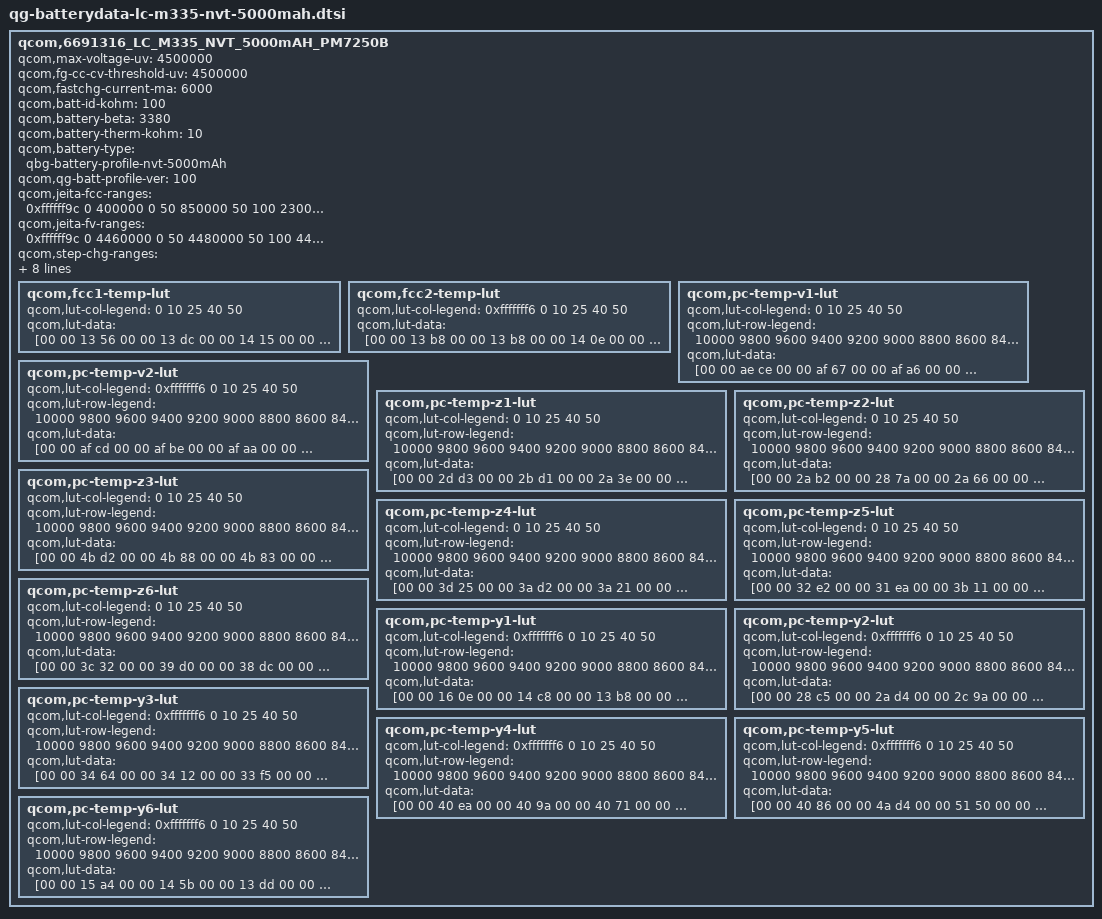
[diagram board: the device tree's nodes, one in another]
// SPDX-License-Identifier: GPL-2.0-only
/* QG battery profile qcom,6691316_LC_M335_NVT_5000mAH_PM7250B (sapphire, reconstructed from stock dtbo) */

qcom,6691316_LC_M335_NVT_5000mAH_PM7250B {
	qcom,max-voltage-uv = <4500000>;
	qcom,fg-cc-cv-threshold-uv = <4500000>;
	qcom,fastchg-current-ma = <6000>;
	qcom,batt-id-kohm = <100>;
	qcom,battery-beta = <3380>;
	qcom,battery-therm-kohm = <10>;
	qcom,battery-type = "qbg-battery-profile-nvt-5000mAh";
	qcom,qg-batt-profile-ver = <100>;
	qcom,jeita-fcc-ranges = <0xffffff9c 0 400000 0 50 850000 50 100
	                         2300000 100 150 3700000 150 350 6000000 350
	                         480 6000000 480 560 2300000>;
	qcom,jeita-fv-ranges = <0xffffff9c 0 4460000 0 50 4480000 50 100
	                        4480000 100 150 4480000 150 350 4450000 350
	                        480 4450000 480 560 4100000>;
	qcom,step-chg-ranges = <3600000 4250000 6000000 4250001 4480000 5400000 4480001 4500000
	                        3920000>;
	qcom,vbat-avg-based-step-chg;
	qcom,taper-fcc;
	qcom,jeita-soft-thresholds = <9556 3725>;
	qcom,jeita-hard-thresholds = <17365 2971>;
	qcom,jeita-soft-hys-thresholds = <8799 4060>;
	qcom,jeita-soft-fcc-ua = <5400000 2500000>;
	qcom,jeita-soft-fv-uv = <4480000 4100000>;

	qcom,fcc1-temp-lut {
		qcom,lut-col-legend = <0 10 25 40 50>;
		qcom,lut-data = [00 00 13 56 00 00 13 dc 00 00 14 15 00 00 14 32 00 00 14 3c];
	};

	qcom,fcc2-temp-lut {
		qcom,lut-col-legend = <0xfffffff6 0 10 25 40 50>;
		qcom,lut-data = [00 00 13 b8 00 00 13 b8 00 00 14 0e 00 00 14 2a 00 00 14 1b 00 00 14 12];
	};

	qcom,pc-temp-v1-lut {
		qcom,lut-col-legend = <0 10 25 40 50>;
		qcom,lut-row-legend = <10000 9800 9600 9400 9200 9000 8800 8600
		                       8400 8200 8000 7800 7600 7400 7200 7000
		                       6800 6600 6400 6200 6000 5800 5600 5400
		                       5200 5000 4800 4600 4400 4200 4000 3800
		                       3600 3400 3200 3000 2800 2600 2400 2200
		                       2000 1800 1600 1400 1200 1000 900 800
		                       700 600 500 400 300 200 100 0>;
		qcom,lut-data = [00 00 ae ce 00 00 af 67 00 00 af a6 00 00 af c5 00 00 af c9 00 00 ad b2 00 00 ad e1 00 00 ae 0c 00 00 ae 1d 00 00 ae 22 00 00 ac b0 00 00 ac e7 00 00 ac eb 00 00 ac e9 00 00 ac f2 00 00 ab d3 00 00 ac 14 00 00 ac 0c 00 00 ab fd 00 00 ac 03 00 00 ab 06 00 00 ab 38 00 00 ab 33 00 00 ab 23 00 00 ab 26 00 00 aa 2b 00 00 aa 61 00 00 aa 57 00 00 aa 47 00 00 aa 48 00 00 a9 44 00 00 a9 80 00 00 a9 78 00 00 a9 6e 00 00 a9 6e 00 00 a8 56 00 00 a8 90 00 00 a8 8c 00 00 a8 86 00 00 a8 89 00 00 a7 60 00 00 a7 97 00 00 a7 94 00 00 a7 90 00 00 a7 99 00 00 a6 65 00 00 a6 9d 00 00 a6 9a 00 00 a6 96 00 00 a6 a2 00 00 a5 6d 00 00 a5 9f 00 00 a5 9d 00 00 a5 9b 00 00 a5 a8 00 00 a4 78 00 00 a4 a4 00 00 a4 a0 00 00 a4 a0 00 00 a4 ad 00 00 a3 86 00 00 a3 ac 00 00 a3 a5 00 00 a3 a6 00 00 a3 b5 00 00 a2 9d 00 00 a2 b9 00 00 a2 ad 00 00 a2 ae 00 00 a2 bf 00 00 a1 bb 00 00 a1 cf 00 00 a1 bf 00 00 a1 bd 00 00 a1 cf 00 00 a0 de 00 00 a0 eb 00 00 a0 d7 00 00 a0 d4 00 00 a0 e4 00 00 a0 07 00 00 a0 0f 00 00 9f f7 00 00 9f f1 00 00 9f ff 00 00 9f 37 00 00 9f 3b 00 00 9f 1f 00 00 9f 17 00 00 9f 23 00 00 9e 70 00 00 9e 6f 00 00 9e 4f 00 00 9e 44 00 00 9e 4f 00 00 9d b0 00 00 9d b1 00 00 9d 8b 00 00 9d 7b 00 00 9d 84 00 00 9c f5 00 00 9c fa 00 00 9c d5 00 00 9c c3 00 00 9c ca 00 00 9c 45 00 00 9c 34 00 00 9c 0f 00 00 9b ff 00 00 9c 07 00 00 9b 8c 00 00 9b 5c 00 00 9b 1e 00 00 9b 17 00 00 9b 24 00 00 9a 9c 00 00 9a 7f 00 00 9a 2b 00 00 9a 25 00 00 9a 35 00 00 99 83 00 00 99 97 00 00 99 61 00 00 99 57 00 00 99 66 00 00 98 b3 00 00 98 b6 00 00 98 b0 00 00 98 9e 00 00 98 ab 00 00 98 29 00 00 98 1f 00 00 98 1d 00 00 98 03 00 00 98 0c 00 00 97 bb 00 00 97 ba 00 00 97 a3 00 00 97 83 00 00 97 87 00 00 97 5d 00 00 97 5b 00 00 97 36 00 00 97 13 00 00 97 13 00 00 97 0c 00 00 96 f5 00 00 96 ce 00 00 96 a9 00 00 96 a5 00 00 96 c1 00 00 96 94 00 00 96 6e 00 00 96 49 00 00 96 40 00 00 96 76 00 00 96 3f 00 00 96 1a 00 00 95 ef 00 00 95 e4 00 00 96 30 00 00 95 f5 00 00 95 d0 00 00 95 9d 00 00 95 91 00 00 95 ee 00 00 95 b2 00 00 95 8c 00 00 95 52 00 00 95 43 00 00 95 b1 00 00 95 78 00 00 95 4e 00 00 95 10 00 00 94 fc 00 00 95 7a 00 00 95 43 00 00 95 15 00 00 94 d3 00 00 94 b9 00 00 95 4e 00 00 95 12 00 00 94 dd 00 00 94 91 00 00 94 6c 00 00 95 23 00 00 94 e5 00 00 94 aa 00 00 94 4c 00 00 94 16 00 00 94 ec 00 00 94 aa 00 00 94 6b 00 00 93 fe 00 00 93 ba 00 00 94 a8 00 00 94 53 00 00 94 13 00 00 93 a2 00 00 93 5b 00 00 94 54 00 00 93 e8 00 00 93 a8 00 00 93 39 00 00 92 f2 00 00 93 da 00 00 93 70 00 00 93 2f 00 00 92 bf 00 00 92 76 00 00 93 49 00 00 92 e1 00 00 92 a1 00 00 92 30 00 00 91 e5 00 00 92 a6 00 00 92 33 00 00 91 f6 00 00 91 8c 00 00 91 46 00 00 92 09 00 00 91 8a 00 00 91 55 00 00 90 f7 00 00 90 b7 00 00 91 72 00 00 91 12 00 00 90 ef 00 00 90 9f 00 00 90 63 00 00 91 35 00 00 90 ed 00 00 90 d3 00 00 90 88 00 00 90 4d 00 00 91 09 00 00 90 d5 00 00 90 be 00 00 90 79 00 00 90 3d 00 00 90 e0 00 00 90 bc 00 00 90 a5 00 00 90 61 00 00 90 23 00 00 90 b7 00 00 90 7a 00 00 90 56 00 00 8f de 00 00 8f 8a 00 00 90 7d 00 00 8f 62 00 00 8f 32 00 00 8e 81 00 00 8e 25 00 00 8f 9e 00 00 8d 7f 00 00 8d 64 00 00 8c 99 00 00 8c 3d 00 00 8d bb 00 00 8a fd 00 00 8b 08 00 00 8a 22 00 00 89 c4 00 00 8a af 00 00 87 6a 00 00 87 cd 00 00 86 b7 00 00 86 60 00 00 80 47 00 00 81 76 00 00 82 c3 00 00 81 4e 00 00 80 f7 00 00 75 30 00 00 75 30 00 00 75 30 00 00 75 30 00 00 75 30];
	};

	qcom,pc-temp-v2-lut {
		qcom,lut-col-legend = <0xfffffff6 0 10 25 40 50>;
		qcom,lut-row-legend = <10000 9800 9600 9400 9200 9000 8800 8600
		                       8400 8200 8000 7800 7600 7400 7200 7000
		                       6800 6600 6400 6200 6000 5800 5600 5400
		                       5200 5000 4800 4600 4400 4200 4000 3800
		                       3600 3400 3200 3000 2800 2600 2400 2200
		                       2000 1800 1600 1400 1200 1000 900 800
		                       700 600 500 400 300 200 100 0>;
		qcom,lut-data = [00 00 af cd 00 00 af be 00 00 af aa 00 00 af 7d 00 00 af 64 00 00 af 50 00 00 ad d1 00 00 ad ee 00 00 ad ee 00 00 ad f3 00 00 ad d3 00 00 ad c1 00 00 ac 2e 00 00 ac 6f 00 00 ac 7f 00 00 ac a5 00 00 ac 7e 00 00 ac 6e 00 00 aa ff 00 00 ab 59 00 00 ab 72 00 00 ab a2 00 00 ab 72 00 00 ab 61 00 00 aa 20 00 00 aa 8e 00 00 aa a9 00 00 aa d6 00 00 aa 9f 00 00 aa 8d 00 00 a9 49 00 00 a9 c4 00 00 a9 dd 00 00 aa 07 00 00 a9 ca 00 00 a9 b7 00 00 a8 5f 00 00 a8 e0 00 00 a8 f9 00 00 a9 25 00 00 a8 e5 00 00 a8 d2 00 00 a7 73 00 00 a7 f4 00 00 a8 0d 00 00 a8 3c 00 00 a7 fa 00 00 a7 e9 00 00 a6 81 00 00 a7 02 00 00 a7 19 00 00 a7 49 00 00 a7 07 00 00 a6 f7 00 00 a5 87 00 00 a6 08 00 00 a6 1b 00 00 a6 4c 00 00 a6 0b 00 00 a5 fc 00 00 a4 8e 00 00 a5 0f 00 00 a5 1d 00 00 a5 4f 00 00 a5 10 00 00 a5 02 00 00 a3 95 00 00 a4 16 00 00 a4 20 00 00 a4 52 00 00 a4 14 00 00 a4 08 00 00 a2 9f 00 00 a3 1e 00 00 a3 26 00 00 a3 56 00 00 a3 1b 00 00 a3 10 00 00 a1 ba 00 00 a2 2c 00 00 a2 31 00 00 a2 5f 00 00 a2 27 00 00 a2 1d 00 00 a0 e2 00 00 a1 3e 00 00 a1 42 00 00 a1 6c 00 00 a1 37 00 00 a1 2e 00 00 a0 05 00 00 a0 5a 00 00 a0 59 00 00 a0 81 00 00 a0 4f 00 00 a0 46 00 00 9f 20 00 00 9f 86 00 00 9f 74 00 00 9f 9d 00 00 9f 6e 00 00 9f 64 00 00 9e 31 00 00 9e b7 00 00 9e 98 00 00 9e c0 00 00 9e 94 00 00 9e 8b 00 00 9d 2e 00 00 9d e5 00 00 9d cc 00 00 9d ef 00 00 9d c4 00 00 9d bd 00 00 9c 18 00 00 9d 10 00 00 9d 03 00 00 9d 20 00 00 9c f8 00 00 9c f5 00 00 9b 12 00 00 9c 26 00 00 9c 1d 00 00 9c 4b 00 00 9c 30 00 00 9c 2f 00 00 9a 21 00 00 9b 0b 00 00 9b 15 00 00 9b 72 00 00 9b 6b 00 00 9b 6d 00 00 99 3f 00 00 99 f2 00 00 9a 19 00 00 9a 8d 00 00 9a 97 00 00 9a 9c 00 00 98 65 00 00 99 14 00 00 99 2e 00 00 99 86 00 00 99 91 00 00 99 9a 00 00 97 96 00 00 98 52 00 00 98 59 00 00 98 93 00 00 98 97 00 00 98 9f 00 00 96 e6 00 00 97 a8 00 00 97 ac 00 00 97 e6 00 00 97 ea 00 00 97 f2 00 00 96 50 00 00 97 12 00 00 97 1c 00 00 97 5a 00 00 97 62 00 00 97 6b 00 00 95 d1 00 00 96 89 00 00 96 99 00 00 96 da 00 00 96 e6 00 00 96 ef 00 00 95 6d 00 00 96 0a 00 00 96 21 00 00 96 63 00 00 96 74 00 00 96 7c 00 00 95 19 00 00 95 96 00 00 95 b3 00 00 95 f7 00 00 96 0b 00 00 96 12 00 00 94 ce 00 00 95 2b 00 00 95 4e 00 00 95 96 00 00 95 ac 00 00 95 b1 00 00 94 8a 00 00 94 c5 00 00 94 f0 00 00 95 3d 00 00 95 54 00 00 95 56 00 00 94 4b 00 00 94 6d 00 00 94 9a 00 00 94 e9 00 00 95 03 00 00 95 03 00 00 94 0d 00 00 94 2c 00 00 94 4a 00 00 94 99 00 00 94 b9 00 00 94 ba 00 00 93 d1 00 00 93 f8 00 00 94 01 00 00 94 49 00 00 94 6a 00 00 94 69 00 00 93 90 00 00 93 c6 00 00 93 c1 00 00 93 fb 00 00 94 0a 00 00 93 fb 00 00 93 4a 00 00 93 97 00 00 93 85 00 00 93 ab 00 00 93 a2 00 00 93 7b 00 00 92 ff 00 00 93 65 00 00 93 45 00 00 93 4f 00 00 93 37 00 00 93 05 00 00 92 ac 00 00 93 26 00 00 92 ff 00 00 92 ea 00 00 92 c8 00 00 92 95 00 00 92 51 00 00 92 dc 00 00 92 af 00 00 92 87 00 00 92 5e 00 00 92 2a 00 00 91 ec 00 00 92 7c 00 00 92 49 00 00 92 2b 00 00 92 04 00 00 91 cd 00 00 91 7a 00 00 91 f8 00 00 91 d1 00 00 91 c0 00 00 91 9e 00 00 91 68 00 00 91 00 00 00 91 66 00 00 91 42 00 00 91 3a 00 00 91 1c 00 00 90 e5 00 00 90 81 00 00 90 c7 00 00 90 9d 00 00 90 9d 00 00 90 84 00 00 90 4a 00 00 90 15 00 00 90 33 00 00 90 12 00 00 90 28 00 00 90 15 00 00 8f e1 00 00 8f ac 00 00 8f c1 00 00 8f c5 00 00 90 06 00 00 8f f9 00 00 8f c5 00 00 8f 79 00 00 8f 8e 00 00 8f 9e 00 00 8f ef 00 00 8f e5 00 00 8f b1 00 00 8f 42 00 00 8f 5f 00 00 8f 6b 00 00 8f cd 00 00 8f cd 00 00 8f 97 00 00 8f 34 00 00 8f 2b 00 00 8f 26 00 00 8f 7b 00 00 8f 97 00 00 8f 5a 00 00 8e d3 00 00 8e ed 00 00 8e 68 00 00 8e 77 00 00 8e b3 00 00 8e 6d 00 00 90 35 00 00 8e 84 00 00 8c e0 00 00 8c a0 00 00 8d 00 00 00 8c b1 00 00 8e ed 00 00 8d aa 00 00 8a 8f 00 00 8a 3c 00 00 8a cc 00 00 8a 7e 00 00 91 23 00 00 8d b4 00 00 87 81 00 00 87 0b 00 00 87 d5 00 00 87 8c 00 00 7a 6a 00 00 8b ff 00 00 84 a3 00 00 82 47 00 00 83 a5 00 00 83 77 00 00 76 38 00 00 77 c9 00 00 7e f6 00 00 7b e9 00 00 7d 77 00 00 7d 66 00 00 72 44 00 00 72 8c 00 00 6d d8 00 00 71 d6 00 00 6d 9a 00 00 6d a1];
	};

	qcom,pc-temp-z1-lut {
		qcom,lut-col-legend = <0 10 25 40 50>;
		qcom,lut-row-legend = <10000 9800 9600 9400 9200 9000 8800 8600
		                       8400 8200 8000 7800 7600 7400 7200 7000
		                       6800 6600 6400 6200 6000 5800 5600 5400
		                       5200 5000 4800 4600 4400 4200 4000 3800
		                       3600 3400 3200 3000 2800 2600 2400 2200
		                       2000 1800 1600 1400 1200 1000 900 800
		                       700 600 500 400 300 200 100 0>;
		qcom,lut-data = [00 00 2d d3 00 00 2b d1 00 00 2a 3e 00 00 29 82 00 00 29 68 00 00 2d e1 00 00 2c 0a 00 00 2a 58 00 00 29 a5 00 00 29 88 00 00 2d ea 00 00 2b fa 00 00 2a 57 00 00 29 9e 00 00 29 85 00 00 2d ed 00 00 2b e4 00 00 2a 4d 00 00 29 99 00 00 29 84 00 00 2d ef 00 00 2b e0 00 00 2a 44 00 00 29 97 00 00 29 83 00 00 2d ef 00 00 2b e0 00 00 2a 3d 00 00 29 97 00 00 29 84 00 00 2d e6 00 00 2b df 00 00 2a 38 00 00 29 98 00 00 29 86 00 00 2d d8 00 00 2b d3 00 00 2a 35 00 00 29 99 00 00 29 89 00 00 2d c0 00 00 2b c3 00 00 2a 34 00 00 29 9b 00 00 29 8c 00 00 2d 9e 00 00 2b bd 00 00 2a 33 00 00 29 9d 00 00 29 90 00 00 2d 8e 00 00 2b b9 00 00 2a 36 00 00 29 a0 00 00 29 94 00 00 2d 87 00 00 2b b7 00 00 2a 39 00 00 29 a4 00 00 29 99 00 00 2d 83 00 00 2b b9 00 00 2a 3e 00 00 29 a8 00 00 29 9d 00 00 2d 84 00 00 2b bb 00 00 2a 43 00 00 29 ad 00 00 29 a2 00 00 2d 85 00 00 2b c0 00 00 2a 49 00 00 29 b2 00 00 29 a6 00 00 2d 85 00 00 2b c7 00 00 2a 50 00 00 29 b7 00 00 29 ac 00 00 2d 84 00 00 2b cd 00 00 2a 58 00 00 29 bc 00 00 29 b2 00 00 2d 85 00 00 2b d2 00 00 2a 5d 00 00 29 c1 00 00 29 b7 00 00 2d 8a 00 00 2b d8 00 00 2a 62 00 00 29 c7 00 00 29 bc 00 00 2d 94 00 00 2b dd 00 00 2a 69 00 00 29 cc 00 00 29 c1 00 00 2d 9d 00 00 2b e5 00 00 2a 70 00 00 29 d2 00 00 29 c6 00 00 2d a4 00 00 2b ea 00 00 2a 77 00 00 29 d7 00 00 29 ca 00 00 2d ad 00 00 2b ef 00 00 2a 7b 00 00 29 db 00 00 29 cf 00 00 2d bb 00 00 2b f3 00 00 2a 7f 00 00 29 df 00 00 29 d3 00 00 2d cd 00 00 2b f5 00 00 2a 86 00 00 29 e3 00 00 29 d7 00 00 2d d3 00 00 2b f7 00 00 2a 8d 00 00 29 e8 00 00 29 da 00 00 2d cb 00 00 2b f9 00 00 2a 94 00 00 29 ec 00 00 29 de 00 00 2d c2 00 00 2b fd 00 00 2a 9a 00 00 29 f0 00 00 29 e2 00 00 2d c3 00 00 2c 01 00 00 2a 9f 00 00 29 f4 00 00 29 e5 00 00 2d c9 00 00 2c 0a 00 00 2a a4 00 00 29 f8 00 00 29 e8 00 00 2d ce 00 00 2c 16 00 00 2a a9 00 00 29 fc 00 00 29 ec 00 00 2d d6 00 00 2c 17 00 00 2a af 00 00 2a 00 00 00 29 ef 00 00 2d de 00 00 2c 13 00 00 2a b5 00 00 2a 03 00 00 29 f2 00 00 2d e0 00 00 2c 11 00 00 2a bb 00 00 2a 07 00 00 29 f4 00 00 2d de 00 00 2c 16 00 00 2a c0 00 00 2a 0b 00 00 29 f7 00 00 2d de 00 00 2c 1e 00 00 2a c5 00 00 2a 0f 00 00 29 fa 00 00 2d e7 00 00 2c 24 00 00 2a cb 00 00 2a 13 00 00 29 fd 00 00 2d f4 00 00 2c 29 00 00 2a d2 00 00 2a 17 00 00 2a 00 00 00 2d fe 00 00 2c 2f 00 00 2a d9 00 00 2a 1a 00 00 2a 02 00 00 2e 08 00 00 2c 38 00 00 2a df 00 00 2a 1c 00 00 2a 03 00 00 2e 0f 00 00 2c 41 00 00 2a e3 00 00 2a 1e 00 00 2a 05 00 00 2e 14 00 00 2c 47 00 00 2a e7 00 00 2a 21 00 00 2a 06 00 00 2e 17 00 00 2c 4d 00 00 2a e9 00 00 2a 23 00 00 2a 08 00 00 2e 20 00 00 2c 5e 00 00 2a f1 00 00 2a 26 00 00 2a 0a 00 00 2e 40 00 00 2c 66 00 00 2a f7 00 00 2a 29 00 00 2a 0b 00 00 2e 33 00 00 2c 63 00 00 2a f8 00 00 2a 2a 00 00 2a 0d 00 00 2e 3d 00 00 2c 6a 00 00 2b 00 00 00 2a 2a 00 00 2a 0d 00 00 2e 4c 00 00 2c 6d 00 00 2a fb 00 00 2a 2c 00 00 2a 0d 00 00 2e 3c 00 00 2c 64 00 00 2b 00 00 00 2a 2e 00 00 2a 0f 00 00 2e 4b 00 00 2c 64 00 00 2b 04 00 00 2a 30 00 00 2a 10 00 00 2e 42 00 00 2c 6e 00 00 2b 09 00 00 2a 33 00 00 2a 12 00 00 2e 53 00 00 2c 7e 00 00 2b 0e 00 00 2a 38 00 00 2a 15 00 00 2e 5f 00 00 2c 83 00 00 2b 18 00 00 2a 3c 00 00 2a 19 00 00 2e 58 00 00 2c aa 00 00 2b 22 00 00 2a 42 00 00 2a 1f 00 00 2e 58 00 00 2c aa 00 00 2b 22 00 00 2a 42 00 00 2a 1f 00 00 2e 58 00 00 2c aa 00 00 2b 22 00 00 2a 42 00 00 2a 1f];
	};

	qcom,pc-temp-z2-lut {
		qcom,lut-col-legend = <0 10 25 40 50>;
		qcom,lut-row-legend = <10000 9800 9600 9400 9200 9000 8800 8600
		                       8400 8200 8000 7800 7600 7400 7200 7000
		                       6800 6600 6400 6200 6000 5800 5600 5400
		                       5200 5000 4800 4600 4400 4200 4000 3800
		                       3600 3400 3200 3000 2800 2600 2400 2200
		                       2000 1800 1600 1400 1200 1000 900 800
		                       700 600 500 400 300 200 100 0>;
		qcom,lut-data = [00 00 2a b2 00 00 28 7a 00 00 2a 66 00 00 2c 9f 00 00 2c de 00 00 29 d1 00 00 29 8f 00 00 2a fc 00 00 2b 6c 00 00 2c 7d 00 00 29 61 00 00 29 da 00 00 2b 56 00 00 2c 99 00 00 2c 84 00 00 29 5b 00 00 2a 09 00 00 2b 22 00 00 2c 7f 00 00 2c ed 00 00 29 4d 00 00 2a 05 00 00 2a f0 00 00 2c 60 00 00 2d 58 00 00 29 3c 00 00 29 da 00 00 2a c6 00 00 2c 3a 00 00 2d 46 00 00 29 1d 00 00 29 b3 00 00 2a aa 00 00 2c 0b 00 00 2d 01 00 00 28 ff 00 00 29 98 00 00 2a a9 00 00 2c 06 00 00 2c eb 00 00 28 eb 00 00 29 85 00 00 2a ad 00 00 2c 1d 00 00 2c e0 00 00 28 da 00 00 29 87 00 00 2a ac 00 00 2c 2a 00 00 2c d7 00 00 28 d6 00 00 29 94 00 00 2a 9f 00 00 2c 22 00 00 2c d8 00 00 28 dd 00 00 29 9f 00 00 2a 96 00 00 2c 13 00 00 2c dd 00 00 28 e6 00 00 29 a6 00 00 2a 99 00 00 2c 07 00 00 2c df 00 00 28 ee 00 00 29 ad 00 00 2a 9e 00 00 2b fc 00 00 2c e4 00 00 28 fc 00 00 29 b8 00 00 2a a2 00 00 2b f7 00 00 2c ef 00 00 29 08 00 00 29 c6 00 00 2a a4 00 00 2b f7 00 00 2d 1a 00 00 29 12 00 00 29 d1 00 00 2a a6 00 00 2b f8 00 00 2d 51 00 00 29 1c 00 00 29 da 00 00 2a aa 00 00 2b fd 00 00 2d 76 00 00 29 26 00 00 29 e0 00 00 2a af 00 00 2c 08 00 00 2d 9d 00 00 29 30 00 00 29 e3 00 00 2a a9 00 00 2c 13 00 00 2d ae 00 00 29 39 00 00 29 e9 00 00 2a 93 00 00 2c 21 00 00 2d bc 00 00 29 3f 00 00 29 f0 00 00 2a 8d 00 00 2c 39 00 00 2d c6 00 00 29 47 00 00 2a 00 00 00 2a c7 00 00 2c 8c 00 00 2e 20 00 00 29 54 00 00 2a 0a 00 00 2b 03 00 00 2d 00 00 00 2e af 00 00 29 67 00 00 29 f4 00 00 2b 01 00 00 2d 39 00 00 2e 9a 00 00 29 6e 00 00 29 cb 00 00 2a f0 00 00 2d 5f 00 00 2d ef 00 00 29 66 00 00 29 c8 00 00 2a ef 00 00 2d 68 00 00 2d 54 00 00 29 5f 00 00 29 e6 00 00 2b 13 00 00 2c bb 00 00 2c cb 00 00 29 5f 00 00 29 fb 00 00 2b 2f 00 00 2b e5 00 00 2c 62 00 00 29 62 00 00 29 fa 00 00 2b 0d 00 00 2b a7 00 00 2c 59 00 00 29 64 00 00 29 f9 00 00 2a cf 00 00 2b 7e 00 00 2c 5b 00 00 29 67 00 00 29 f8 00 00 2a bc 00 00 2b 76 00 00 2c 61 00 00 29 6a 00 00 29 f8 00 00 2a b9 00 00 2b 94 00 00 2c 8d 00 00 29 6b 00 00 29 f9 00 00 2a bb 00 00 2b bf 00 00 2c cc 00 00 29 6e 00 00 2a 03 00 00 2a ca 00 00 2b f4 00 00 2d 11 00 00 29 71 00 00 2a 11 00 00 2a e1 00 00 2c 2f 00 00 2d 5c 00 00 29 76 00 00 2a 16 00 00 2a f1 00 00 2c 4e 00 00 2d 90 00 00 29 7c 00 00 2a 18 00 00 2a ff 00 00 2c 69 00 00 2d ca 00 00 29 82 00 00 2a 1c 00 00 2b 11 00 00 2c 80 00 00 2d ea 00 00 29 8a 00 00 2a 2e 00 00 2b 2f 00 00 2c af 00 00 2d f6 00 00 29 8d 00 00 2a 3e 00 00 2b 48 00 00 2c e0 00 00 2e 01 00 00 29 82 00 00 2a 35 00 00 2b 37 00 00 2c d6 00 00 2d f4 00 00 29 7a 00 00 2a 1b 00 00 2b 0e 00 00 2c af 00 00 2d cd 00 00 29 7c 00 00 2a 16 00 00 2b 2d 00 00 2c a6 00 00 2d d6 00 00 29 41 00 00 2a 2d 00 00 2b 4d 00 00 2c bc 00 00 2d da 00 00 2a 04 00 00 2a 98 00 00 2b 2f 00 00 2c f2 00 00 2e 1a 00 00 32 f5 00 00 2a 7a 00 00 2b 05 00 00 2c c5 00 00 2e 50 00 00 29 f9 00 00 2a 9e 00 00 2a ee 00 00 2c ea 00 00 2e 6a 00 00 33 89 00 00 2b 02 00 00 2a e3 00 00 2d 17 00 00 2e ba 00 00 2f 1a 00 00 2a ea 00 00 2b 23 00 00 2c f3 00 00 2d 7d 00 00 31 66 00 00 2b 11 00 00 2b 22 00 00 2c 1f 00 00 2c 85 00 00 29 b3 00 00 2a fd 00 00 2a f2 00 00 2b bb 00 00 2c 33 00 00 28 29 00 00 2a aa 00 00 2a a4 00 00 2b 6e 00 00 2c 0d 00 00 29 0b 00 00 29 bc 00 00 2a 40 00 00 2b 10 00 00 2b d2 00 00 29 0b 00 00 29 bc 00 00 2a 40 00 00 2b 10 00 00 2b d2 00 00 29 0b 00 00 29 bc 00 00 2a 40 00 00 2b 10 00 00 2b d2];
	};

	qcom,pc-temp-z3-lut {
		qcom,lut-col-legend = <0 10 25 40 50>;
		qcom,lut-row-legend = <10000 9800 9600 9400 9200 9000 8800 8600
		                       8400 8200 8000 7800 7600 7400 7200 7000
		                       6800 6600 6400 6200 6000 5800 5600 5400
		                       5200 5000 4800 4600 4400 4200 4000 3800
		                       3600 3400 3200 3000 2800 2600 2400 2200
		                       2000 1800 1600 1400 1200 1000 900 800
		                       700 600 500 400 300 200 100 0>;
		qcom,lut-data = [00 00 4b d2 00 00 4b 88 00 00 4b 83 00 00 4b 62 00 00 4b 62 00 00 4c 28 00 00 4b f5 00 00 4b aa 00 00 4b 7d 00 00 4b 77 00 00 4c 5a 00 00 4c 09 00 00 4b bf 00 00 4b 8e 00 00 4b 7a 00 00 4c 69 00 00 4c 12 00 00 4b c0 00 00 4b 92 00 00 4b 7d 00 00 4c 72 00 00 4c 14 00 00 4b c1 00 00 4b 93 00 00 4b 7e 00 00 4c 75 00 00 4c 15 00 00 4b c1 00 00 4b 90 00 00 4b 7d 00 00 4c 76 00 00 4c 14 00 00 4b c1 00 00 4b 8a 00 00 4b 7b 00 00 4c 76 00 00 4c 12 00 00 4b bf 00 00 4b 87 00 00 4b 79 00 00 4c 75 00 00 4c 10 00 00 4b b8 00 00 4b 87 00 00 4b 78 00 00 4c 72 00 00 4c 0b 00 00 4b b2 00 00 4b 86 00 00 4b 76 00 00 4c 6e 00 00 4c 02 00 00 4b ab 00 00 4b 82 00 00 4b 74 00 00 4c 68 00 00 4b fc 00 00 4b a7 00 00 4b 7c 00 00 4b 72 00 00 4c 62 00 00 4b f9 00 00 4b a6 00 00 4b 7b 00 00 4b 6f 00 00 4c 5a 00 00 4b f7 00 00 4b a5 00 00 4b 7a 00 00 4b 6d 00 00 4c 52 00 00 4b f3 00 00 4b a3 00 00 4b 79 00 00 4b 6a 00 00 4c 4d 00 00 4b f0 00 00 4b 9e 00 00 4b 75 00 00 4b 68 00 00 4c 4a 00 00 4b ed 00 00 4b 9a 00 00 4b 71 00 00 4b 66 00 00 4c 47 00 00 4b ea 00 00 4b 99 00 00 4b 70 00 00 4b 65 00 00 4c 44 00 00 4b e8 00 00 4b 98 00 00 4b 6f 00 00 4b 63 00 00 4c 40 00 00 4b e6 00 00 4b 97 00 00 4b 6f 00 00 4b 62 00 00 4c 3d 00 00 4b e3 00 00 4b 96 00 00 4b 6d 00 00 4b 61 00 00 4c 3b 00 00 4b e3 00 00 4b 95 00 00 4b 6c 00 00 4b 60 00 00 4c 3a 00 00 4b ea 00 00 4b 9c 00 00 4b 6f 00 00 4b 65 00 00 4c 3f 00 00 4b ef 00 00 4b a3 00 00 4b 77 00 00 4b 6e 00 00 4c 4c 00 00 4b ec 00 00 4b a0 00 00 4b 7e 00 00 4b 75 00 00 4c 51 00 00 4b e7 00 00 4b 95 00 00 4b 88 00 00 4b 7a 00 00 4c 4e 00 00 4b e5 00 00 4b 92 00 00 4b 8c 00 00 4b 7c 00 00 4c 4a 00 00 4b e5 00 00 4b a1 00 00 4b 8a 00 00 4b 7b 00 00 4c 48 00 00 4b e6 00 00 4b ae 00 00 4b 88 00 00 4b 79 00 00 4c 46 00 00 4b ec 00 00 4b af 00 00 4b 85 00 00 4b 77 00 00 4c 44 00 00 4b f3 00 00 4b af 00 00 4b 80 00 00 4b 74 00 00 4c 43 00 00 4b f3 00 00 4b ae 00 00 4b 7d 00 00 4b 70 00 00 4c 43 00 00 4b f1 00 00 4b a9 00 00 4b 7a 00 00 4b 6b 00 00 4c 43 00 00 4b ee 00 00 4b a5 00 00 4b 77 00 00 4b 66 00 00 4c 42 00 00 4b ec 00 00 4b a2 00 00 4b 73 00 00 4b 62 00 00 4c 41 00 00 4b ea 00 00 4b a1 00 00 4b 70 00 00 4b 5f 00 00 4c 40 00 00 4b e9 00 00 4b 9f 00 00 4b 70 00 00 4b 5f 00 00 4c 3e 00 00 4b e8 00 00 4b 9e 00 00 4b 70 00 00 4b 62 00 00 4c 3b 00 00 4b e7 00 00 4b 9d 00 00 4b 71 00 00 4b 64 00 00 4c 35 00 00 4b e4 00 00 4b 9a 00 00 4b 70 00 00 4b 66 00 00 4c 30 00 00 4b e0 00 00 4b 97 00 00 4b 70 00 00 4b 67 00 00 4c 2c 00 00 4b dd 00 00 4b 95 00 00 4b 70 00 00 4b 67 00 00 4c 28 00 00 4b da 00 00 4b 94 00 00 4b 71 00 00 4b 68 00 00 4c 21 00 00 4b d8 00 00 4b 94 00 00 4b 72 00 00 4b 69 00 00 4b 9b 00 00 4b d1 00 00 4b 93 00 00 4b 71 00 00 4b 68 00 00 4b 3d 00 00 4b c0 00 00 4b 89 00 00 4b 69 00 00 4b 5d 00 00 4b 3c 00 00 4b bf 00 00 4b 86 00 00 4b 69 00 00 4b 5b 00 00 4b 3d 00 00 4b b1 00 00 4b 85 00 00 4b 64 00 00 4b 5a 00 00 4b 3a 00 00 4b 92 00 00 4b 84 00 00 4b 61 00 00 4b 57 00 00 4b 3a 00 00 4b 9c 00 00 4b 82 00 00 4b 68 00 00 4b 64 00 00 4b 3b 00 00 4b 93 00 00 4b 85 00 00 4b 72 00 00 4b 68 00 00 4b 3d 00 00 4b 8a 00 00 4b 8b 00 00 4b 74 00 00 4b 68 00 00 4b 41 00 00 4b 85 00 00 4b 8e 00 00 4b 75 00 00 4b 6a 00 00 4c 14 00 00 4b c9 00 00 4b 91 00 00 4b 79 00 00 4b 6b 00 00 4c 14 00 00 4b c9 00 00 4b 91 00 00 4b 79 00 00 4b 6b 00 00 4c 14 00 00 4b c9 00 00 4b 91 00 00 4b 79 00 00 4b 6b];
	};

	qcom,pc-temp-z4-lut {
		qcom,lut-col-legend = <0 10 25 40 50>;
		qcom,lut-row-legend = <10000 9800 9600 9400 9200 9000 8800 8600
		                       8400 8200 8000 7800 7600 7400 7200 7000
		                       6800 6600 6400 6200 6000 5800 5600 5400
		                       5200 5000 4800 4600 4400 4200 4000 3800
		                       3600 3400 3200 3000 2800 2600 2400 2200
		                       2000 1800 1600 1400 1200 1000 900 800
		                       700 600 500 400 300 200 100 0>;
		qcom,lut-data = [00 00 3d 25 00 00 3a d2 00 00 3a 21 00 00 39 b5 00 00 39 a6 00 00 3c e9 00 00 3c 09 00 00 39 f0 00 00 39 77 00 00 39 5e 00 00 3c 93 00 00 3b 90 00 00 3a 46 00 00 39 a8 00 00 39 7d 00 00 3c 02 00 00 3a c8 00 00 3a 05 00 00 39 95 00 00 39 73 00 00 3b 4a 00 00 3a 60 00 00 39 cd 00 00 39 7e 00 00 39 65 00 00 3a d1 00 00 3a 1d 00 00 39 aa 00 00 39 6f 00 00 39 5a 00 00 3a 81 00 00 39 eb 00 00 39 8e 00 00 39 63 00 00 39 51 00 00 3a 42 00 00 39 c5 00 00 39 7d 00 00 39 5a 00 00 39 4b 00 00 3a 10 00 00 39 a7 00 00 39 70 00 00 39 53 00 00 39 47 00 00 39 e8 00 00 39 93 00 00 39 67 00 00 39 4e 00 00 39 43 00 00 39 c7 00 00 39 83 00 00 39 62 00 00 39 4b 00 00 39 3f 00 00 39 a9 00 00 39 78 00 00 39 5e 00 00 39 48 00 00 39 3c 00 00 39 95 00 00 39 71 00 00 39 57 00 00 39 43 00 00 39 38 00 00 39 8c 00 00 39 6c 00 00 39 50 00 00 39 3c 00 00 39 35 00 00 39 87 00 00 39 67 00 00 39 4b 00 00 39 37 00 00 39 31 00 00 39 82 00 00 39 63 00 00 39 48 00 00 39 34 00 00 39 2d 00 00 39 7e 00 00 39 60 00 00 39 46 00 00 39 32 00 00 39 29 00 00 39 7a 00 00 39 5e 00 00 39 42 00 00 39 2d 00 00 39 24 00 00 39 78 00 00 39 5c 00 00 39 3e 00 00 39 28 00 00 39 20 00 00 39 77 00 00 39 5a 00 00 39 3c 00 00 39 25 00 00 39 1d 00 00 39 75 00 00 39 57 00 00 39 3b 00 00 39 24 00 00 39 1b 00 00 39 72 00 00 39 58 00 00 39 3b 00 00 39 24 00 00 39 19 00 00 39 70 00 00 39 63 00 00 39 52 00 00 39 39 00 00 39 29 00 00 39 86 00 00 39 75 00 00 39 75 00 00 39 58 00 00 39 43 00 00 39 c1 00 00 39 98 00 00 39 8d 00 00 39 5d 00 00 39 48 00 00 39 d9 00 00 39 c3 00 00 39 a2 00 00 39 5b 00 00 39 47 00 00 39 d7 00 00 39 c8 00 00 39 a6 00 00 39 59 00 00 39 46 00 00 39 d4 00 00 39 b2 00 00 39 8c 00 00 39 51 00 00 39 40 00 00 39 cc 00 00 39 9b 00 00 39 6f 00 00 39 47 00 00 39 38 00 00 39 bc 00 00 39 8b 00 00 39 63 00 00 39 41 00 00 39 33 00 00 39 ae 00 00 39 7f 00 00 39 5b 00 00 39 3c 00 00 39 2f 00 00 39 a5 00 00 39 7a 00 00 39 56 00 00 39 37 00 00 39 2b 00 00 39 9e 00 00 39 78 00 00 39 52 00 00 39 33 00 00 39 28 00 00 39 9b 00 00 39 77 00 00 39 51 00 00 39 30 00 00 39 26 00 00 39 99 00 00 39 77 00 00 39 51 00 00 39 30 00 00 39 25 00 00 39 96 00 00 39 77 00 00 39 52 00 00 39 2f 00 00 39 24 00 00 39 93 00 00 39 77 00 00 39 53 00 00 39 31 00 00 39 26 00 00 39 90 00 00 39 75 00 00 39 55 00 00 39 39 00 00 39 2f 00 00 39 8a 00 00 39 72 00 00 39 57 00 00 39 3d 00 00 39 34 00 00 39 80 00 00 39 70 00 00 39 57 00 00 39 3d 00 00 39 32 00 00 39 75 00 00 39 6c 00 00 39 58 00 00 39 3c 00 00 39 2e 00 00 39 6d 00 00 39 64 00 00 39 54 00 00 39 39 00 00 39 2b 00 00 39 63 00 00 39 55 00 00 39 49 00 00 39 32 00 00 39 28 00 00 39 52 00 00 39 4d 00 00 39 43 00 00 39 30 00 00 39 25 00 00 39 b4 00 00 39 42 00 00 39 3c 00 00 39 2e 00 00 39 22 00 00 3a 03 00 00 39 30 00 00 39 2f 00 00 39 26 00 00 39 1f 00 00 3a 02 00 00 39 2a 00 00 39 29 00 00 39 1d 00 00 39 19 00 00 39 fe 00 00 39 32 00 00 39 20 00 00 39 16 00 00 39 0f 00 00 39 fa 00 00 39 4e 00 00 39 1a 00 00 39 13 00 00 39 0c 00 00 39 f7 00 00 39 42 00 00 39 21 00 00 39 17 00 00 39 0d 00 00 39 f3 00 00 39 54 00 00 39 29 00 00 39 14 00 00 39 0f 00 00 39 f4 00 00 39 62 00 00 39 26 00 00 39 14 00 00 39 10 00 00 3a 00 00 00 39 6e 00 00 39 23 00 00 39 14 00 00 39 12 00 00 39 62 00 00 39 32 00 00 39 25 00 00 39 15 00 00 39 14 00 00 39 62 00 00 39 32 00 00 39 25 00 00 39 15 00 00 39 14 00 00 39 62 00 00 39 32 00 00 39 25 00 00 39 15 00 00 39 14];
	};

	qcom,pc-temp-z5-lut {
		qcom,lut-col-legend = <0 10 25 40 50>;
		qcom,lut-row-legend = <10000 9800 9600 9400 9200 9000 8800 8600
		                       8400 8200 8000 7800 7600 7400 7200 7000
		                       6800 6600 6400 6200 6000 5800 5600 5400
		                       5200 5000 4800 4600 4400 4200 4000 3800
		                       3600 3400 3200 3000 2800 2600 2400 2200
		                       2000 1800 1600 1400 1200 1000 900 800
		                       700 600 500 400 300 200 100 0>;
		qcom,lut-data = [00 00 32 e2 00 00 31 ea 00 00 3b 11 00 00 39 89 00 00 3e c6 00 00 3a 95 00 00 40 d1 00 00 51 10 00 00 55 15 00 00 64 f6 00 00 40 cf 00 00 45 67 00 00 4e 67 00 00 59 09 00 00 5b ed 00 00 45 82 00 00 4b 61 00 00 52 04 00 00 5e 4e 00 00 5f 70 00 00 49 76 00 00 50 5f 00 00 56 2e 00 00 61 62 00 00 64 64 00 00 4c f9 00 00 55 05 00 00 5a ea 00 00 61 47 00 00 68 5a 00 00 51 06 00 00 59 c5 00 00 5f 68 00 00 60 b8 00 00 6c 48 00 00 55 75 00 00 5f 04 00 00 62 5c 00 00 61 b6 00 00 6e 8f 00 00 5a 73 00 00 64 38 00 00 64 9e 00 00 66 55 00 00 6f 8d 00 00 60 7d 00 00 68 ac 00 00 64 f6 00 00 68 fd 00 00 6f c8 00 00 67 aa 00 00 6c ba 00 00 62 d4 00 00 65 99 00 00 6f cd 00 00 72 1a 00 00 70 91 00 00 61 28 00 00 61 2e 00 00 6f fc 00 00 79 8a 00 00 74 92 00 00 64 b0 00 00 63 36 00 00 70 08 00 00 7a 8a 00 00 77 e1 00 00 6b 84 00 00 6b 77 00 00 6f c1 00 00 7a cd 00 00 79 97 00 00 6c b3 00 00 6e a4 00 00 6f 99 00 00 7b cc 00 00 7a bd 00 00 6a 1d 00 00 6a 7d 00 00 71 2d 00 00 80 11 00 00 7c 7e 00 00 68 7f 00 00 66 83 00 00 74 31 00 00 84 61 00 00 7f b4 00 00 6b d3 00 00 6a 19 00 00 78 8b 00 00 85 f9 00 00 83 15 00 00 72 30 00 00 73 20 00 00 7f 27 00 00 87 54 00 00 85 a5 00 00 76 be 00 00 78 45 00 00 85 31 00 00 89 27 00 00 88 bb 00 00 7a a4 00 00 7a fa 00 00 8b f3 00 00 8c d2 00 00 90 68 00 00 7f f6 00 00 7c ec 00 00 91 a2 00 00 93 35 00 00 aa 9b 00 00 8e be 00 00 7e fb 00 00 94 c3 00 00 a9 60 00 00 bd 62 00 00 9c ce 00 00 80 77 00 00 95 42 00 00 d4 6c 00 00 ac 3a 00 00 8e 35 00 00 7b 9e 00 00 8c 5e 00 00 e3 d0 00 00 8a 12 00 00 62 bd 00 00 69 60 00 00 70 7e 00 00 c9 2e 00 00 7a f5 00 00 53 d5 00 00 60 a8 00 00 62 36 00 00 a9 3a 00 00 73 90 00 00 5d 8f 00 00 66 7f 00 00 67 23 00 00 9e 05 00 00 70 b2 00 00 6b 6d 00 00 6d 26 00 00 6f a3 00 00 97 52 00 00 7d 91 00 00 7a 0b 00 00 6f 90 00 00 78 42 00 00 95 70 00 00 94 14 00 00 8a cc 00 00 74 d1 00 00 81 cf 00 00 99 ab 00 00 a1 48 00 00 94 c3 00 00 7a 70 00 00 84 b5 00 00 a0 a0 00 00 aa d8 00 00 9a dc 00 00 84 d9 00 00 83 d4 00 00 a8 28 00 00 af a2 00 00 a1 0d 00 00 8f 16 00 00 83 0d 00 00 b1 f9 00 00 b0 fa 00 00 ab 2e 00 00 95 c7 00 00 84 e9 00 00 b6 1f 00 00 b1 e9 00 00 b4 a9 00 00 9a ca 00 00 88 92 00 00 b5 03 00 00 b3 67 00 00 b5 1a 00 00 9a e7 00 00 89 1c 00 00 b3 8c 00 00 b6 45 00 00 b0 42 00 00 96 3f 00 00 87 62 00 00 b3 13 00 00 b7 54 00 00 a9 0b 00 00 90 48 00 00 86 56 00 00 b2 1a 00 00 b1 5a 00 00 98 5d 00 00 87 c1 00 00 89 ed 00 00 b0 8a 00 00 a8 bb 00 00 88 12 00 00 7f e4 00 00 90 60 00 00 aa 80 00 00 a2 11 00 00 84 a9 00 00 7f c4 00 00 98 2f 00 00 a6 3b 00 00 9d 07 00 00 83 75 00 00 82 dd 00 00 a2 dc 00 00 a1 a0 00 00 9e ca 00 00 83 75 00 00 80 99 00 00 9a 84 00 00 5c 1f 00 00 9f 73 00 00 83 77 00 00 76 ef 00 00 86 88 00 00 2e 1c 00 00 96 fd 00 00 7d 63 00 00 6a c6 00 00 65 33 00 00 2d ed 00 00 97 ef 00 00 79 53 00 00 7d 71 00 00 6a 7f 00 00 2d 98 00 00 6e 3f 00 00 81 ff 00 00 7c 67 00 00 8a 5b 00 00 2d 67 00 00 43 c7 00 00 8a d8 00 00 7d 40 00 00 87 e6 00 00 2d 48 00 00 53 9d 00 00 74 04 00 00 73 53 00 00 be 21 00 00 2d 5c 00 00 47 57 00 00 63 96 00 00 8f df 00 00 c6 9f 00 00 2d 79 00 00 3e 41 00 00 69 35 00 00 9f 27 00 00 c0 73 00 00 2e 87 00 00 3a d9 00 00 6f 4c 00 00 93 e8 00 00 be 5f 00 00 a5 57 00 00 8e e4 00 00 6c 3a 00 00 a9 92 00 00 a5 7e 00 00 a5 57 00 00 8e e4 00 00 6c 3a 00 00 a9 92 00 00 a5 7e 00 00 a5 57 00 00 8e e4 00 00 6c 3a 00 00 a9 92 00 00 a5 7e];
	};

	qcom,pc-temp-z6-lut {
		qcom,lut-col-legend = <0 10 25 40 50>;
		qcom,lut-row-legend = <10000 9800 9600 9400 9200 9000 8800 8600
		                       8400 8200 8000 7800 7600 7400 7200 7000
		                       6800 6600 6400 6200 6000 5800 5600 5400
		                       5200 5000 4800 4600 4400 4200 4000 3800
		                       3600 3400 3200 3000 2800 2600 2400 2200
		                       2000 1800 1600 1400 1200 1000 900 800
		                       700 600 500 400 300 200 100 0>;
		qcom,lut-data = [00 00 3c 32 00 00 39 d0 00 00 38 dc 00 00 38 67 00 00 38 56 00 00 3c 15 00 00 3a 82 00 00 38 d9 00 00 38 5e 00 00 38 49 00 00 3b e8 00 00 3a 4a 00 00 39 04 00 00 38 7a 00 00 38 57 00 00 3b 99 00 00 39 eb 00 00 38 e5 00 00 38 73 00 00 38 54 00 00 3b 30 00 00 39 b4 00 00 38 ca 00 00 38 6a 00 00 38 4f 00 00 3a e5 00 00 39 8e 00 00 38 b9 00 00 38 61 00 00 38 4b 00 00 3a af 00 00 39 6f 00 00 38 ab 00 00 38 59 00 00 38 46 00 00 3a 82 00 00 39 57 00 00 38 a0 00 00 38 54 00 00 38 42 00 00 3a 5b 00 00 39 43 00 00 38 96 00 00 38 51 00 00 38 40 00 00 3a 39 00 00 39 32 00 00 38 90 00 00 38 4e 00 00 38 3e 00 00 3a 1c 00 00 39 24 00 00 38 8a 00 00 38 4b 00 00 38 3c 00 00 3a 01 00 00 39 1b 00 00 38 86 00 00 38 48 00 00 38 3a 00 00 39 ed 00 00 39 15 00 00 38 83 00 00 38 45 00 00 38 38 00 00 39 e3 00 00 39 11 00 00 38 80 00 00 38 43 00 00 38 36 00 00 39 dc 00 00 39 0d 00 00 38 7d 00 00 38 41 00 00 38 34 00 00 39 d8 00 00 39 0a 00 00 38 7b 00 00 38 3e 00 00 38 32 00 00 39 d5 00 00 39 08 00 00 38 79 00 00 38 3b 00 00 38 30 00 00 39 d2 00 00 39 06 00 00 38 78 00 00 38 3a 00 00 38 2e 00 00 39 d0 00 00 39 05 00 00 38 77 00 00 38 38 00 00 38 2c 00 00 39 cf 00 00 39 04 00 00 38 77 00 00 38 38 00 00 38 2b 00 00 39 ce 00 00 39 03 00 00 38 77 00 00 38 37 00 00 38 2a 00 00 39 cf 00 00 39 03 00 00 38 77 00 00 38 37 00 00 38 2a 00 00 39 cf 00 00 39 0c 00 00 38 86 00 00 38 42 00 00 38 33 00 00 39 dd 00 00 39 19 00 00 38 9a 00 00 38 55 00 00 38 44 00 00 39 ff 00 00 39 29 00 00 38 a3 00 00 38 5d 00 00 38 4b 00 00 3a 0d 00 00 39 3a 00 00 38 a9 00 00 38 62 00 00 38 4f 00 00 3a 0d 00 00 39 3c 00 00 38 aa 00 00 38 63 00 00 38 50 00 00 3a 0c 00 00 39 33 00 00 38 a7 00 00 38 60 00 00 38 4e 00 00 3a 0a 00 00 39 2d 00 00 38 a4 00 00 38 5b 00 00 38 4a 00 00 3a 04 00 00 39 2d 00 00 38 a1 00 00 38 57 00 00 38 47 00 00 3a 01 00 00 39 2c 00 00 38 9f 00 00 38 54 00 00 38 44 00 00 39 fe 00 00 39 2c 00 00 38 9d 00 00 38 50 00 00 38 41 00 00 39 fc 00 00 39 2b 00 00 38 99 00 00 38 4d 00 00 38 3d 00 00 39 fd 00 00 39 2a 00 00 38 98 00 00 38 4b 00 00 38 3a 00 00 39 fe 00 00 39 2c 00 00 38 98 00 00 38 49 00 00 38 38 00 00 39 ff 00 00 39 2e 00 00 38 99 00 00 38 48 00 00 38 36 00 00 3a 03 00 00 39 30 00 00 38 9a 00 00 38 49 00 00 38 37 00 00 3a 06 00 00 39 31 00 00 38 9c 00 00 38 4d 00 00 38 3d 00 00 3a 06 00 00 39 32 00 00 38 9e 00 00 38 50 00 00 38 40 00 00 3a 05 00 00 39 33 00 00 38 9f 00 00 38 50 00 00 38 40 00 00 3a 05 00 00 39 33 00 00 38 9f 00 00 38 50 00 00 38 3f 00 00 3a 08 00 00 39 32 00 00 38 9d 00 00 38 4f 00 00 38 3f 00 00 3a 0b 00 00 39 2f 00 00 38 9a 00 00 38 4d 00 00 38 3e 00 00 3a 0a 00 00 39 2f 00 00 38 9a 00 00 38 4d 00 00 38 3d 00 00 3a 00 00 00 39 2e 00 00 38 99 00 00 38 4c 00 00 38 3c 00 00 39 fd 00 00 39 24 00 00 38 90 00 00 38 45 00 00 38 36 00 00 39 fa 00 00 39 22 00 00 38 8d 00 00 38 41 00 00 38 32 00 00 39 fd 00 00 39 20 00 00 38 88 00 00 38 3c 00 00 38 2d 00 00 39 fc 00 00 39 1e 00 00 38 87 00 00 38 39 00 00 38 2a 00 00 39 fc 00 00 39 21 00 00 38 8b 00 00 38 3f 00 00 38 32 00 00 3a 02 00 00 39 29 00 00 38 91 00 00 38 44 00 00 38 35 00 00 3a 09 00 00 39 2f 00 00 38 95 00 00 38 46 00 00 38 37 00 00 3a 19 00 00 39 39 00 00 38 99 00 00 38 47 00 00 38 39 00 00 3a 46 00 00 39 4b 00 00 38 9f 00 00 38 4c 00 00 38 3c 00 00 3a 46 00 00 39 4b 00 00 38 9f 00 00 38 4c 00 00 38 3c 00 00 3a 46 00 00 39 4b 00 00 38 9f 00 00 38 4c 00 00 38 3c];
	};

	qcom,pc-temp-y1-lut {
		qcom,lut-col-legend = <0xfffffff6 0 10 25 40 50>;
		qcom,lut-row-legend = <10000 9800 9600 9400 9200 9000 8800 8600
		                       8400 8200 8000 7800 7600 7400 7200 7000
		                       6800 6600 6400 6200 6000 5800 5600 5400
		                       5200 5000 4800 4600 4400 4200 4000 3800
		                       3600 3400 3200 3000 2800 2600 2400 2200
		                       2000 1800 1600 1400 1200 1000 900 800
		                       700 600 500 400 300 200 100 0>;
		qcom,lut-data = [00 00 16 0e 00 00 14 c8 00 00 13 b8 00 00 12 ba 00 00 12 4c 00 00 12 2d 00 00 16 2d 00 00 14 c1 00 00 13 b8 00 00 12 bd 00 00 12 4c 00 00 12 2f 00 00 16 44 00 00 14 b9 00 00 13 b6 00 00 12 be 00 00 12 4b 00 00 12 32 00 00 16 53 00 00 14 b3 00 00 13 b3 00 00 12 bd 00 00 12 4b 00 00 12 34 00 00 16 5c 00 00 14 af 00 00 13 b0 00 00 12 bc 00 00 12 4b 00 00 12 36 00 00 16 5e 00 00 14 ae 00 00 13 af 00 00 12 bb 00 00 12 4b 00 00 12 38 00 00 16 56 00 00 14 af 00 00 13 af 00 00 12 b9 00 00 12 4b 00 00 12 3a 00 00 16 4a 00 00 14 b2 00 00 13 ae 00 00 12 b7 00 00 12 4b 00 00 12 3c 00 00 16 4b 00 00 14 b4 00 00 13 ae 00 00 12 b7 00 00 12 4c 00 00 12 3e 00 00 16 58 00 00 14 b5 00 00 13 ad 00 00 12 ba 00 00 12 4d 00 00 12 40 00 00 16 65 00 00 14 b7 00 00 13 ad 00 00 12 bb 00 00 12 4f 00 00 12 41 00 00 16 73 00 00 14 ba 00 00 13 af 00 00 12 bb 00 00 12 51 00 00 12 44 00 00 16 7f 00 00 14 be 00 00 13 b2 00 00 12 bb 00 00 12 52 00 00 12 46 00 00 16 7a 00 00 14 c4 00 00 13 b1 00 00 12 bc 00 00 12 54 00 00 12 48 00 00 16 65 00 00 14 cb 00 00 13 b1 00 00 12 bd 00 00 12 55 00 00 12 4a 00 00 16 5b 00 00 14 d0 00 00 13 b2 00 00 12 bf 00 00 12 57 00 00 12 4c 00 00 16 69 00 00 14 d3 00 00 13 b6 00 00 12 c2 00 00 12 5a 00 00 12 4e 00 00 16 79 00 00 14 d6 00 00 13 b8 00 00 12 c5 00 00 12 5c 00 00 12 51 00 00 16 7a 00 00 14 d4 00 00 13 b6 00 00 12 c7 00 00 12 5e 00 00 12 52 00 00 16 79 00 00 14 cd 00 00 13 b2 00 00 12 c9 00 00 12 5f 00 00 12 53 00 00 16 78 00 00 14 cb 00 00 13 b3 00 00 12 ca 00 00 12 61 00 00 12 55 00 00 16 7a 00 00 14 ce 00 00 13 b8 00 00 12 cc 00 00 12 63 00 00 12 56 00 00 16 7c 00 00 14 d1 00 00 13 bc 00 00 12 ce 00 00 12 65 00 00 12 57 00 00 16 81 00 00 14 d2 00 00 13 c1 00 00 12 d1 00 00 12 66 00 00 12 59 00 00 16 8d 00 00 14 d0 00 00 13 c5 00 00 12 d4 00 00 12 68 00 00 12 5c 00 00 16 91 00 00 14 d0 00 00 13 c6 00 00 12 d7 00 00 12 6a 00 00 12 5d 00 00 16 8f 00 00 14 d3 00 00 13 c6 00 00 12 da 00 00 12 6b 00 00 12 5f 00 00 16 8c 00 00 14 d6 00 00 13 c6 00 00 12 dc 00 00 12 6d 00 00 12 60 00 00 16 8c 00 00 14 d9 00 00 13 c8 00 00 12 df 00 00 12 6e 00 00 12 61 00 00 16 8e 00 00 14 dd 00 00 13 c9 00 00 12 e1 00 00 12 70 00 00 12 62 00 00 16 8f 00 00 14 e0 00 00 13 cd 00 00 12 e5 00 00 12 72 00 00 12 63 00 00 16 91 00 00 14 e6 00 00 13 d5 00 00 12 e8 00 00 12 74 00 00 12 65 00 00 16 94 00 00 14 ea 00 00 13 d9 00 00 12 e9 00 00 12 76 00 00 12 66 00 00 16 90 00 00 14 ea 00 00 13 d9 00 00 12 eb 00 00 12 78 00 00 12 68 00 00 16 89 00 00 14 e9 00 00 13 d9 00 00 12 ec 00 00 12 7a 00 00 12 69 00 00 16 86 00 00 14 e9 00 00 13 da 00 00 12 ed 00 00 12 7b 00 00 12 6a 00 00 16 82 00 00 14 ee 00 00 13 dc 00 00 12 ef 00 00 12 7c 00 00 12 6b 00 00 16 7f 00 00 14 f2 00 00 13 dd 00 00 12 f1 00 00 12 7e 00 00 12 6d 00 00 16 83 00 00 14 ed 00 00 13 de 00 00 12 f4 00 00 12 7f 00 00 12 6e 00 00 16 8a 00 00 14 e4 00 00 13 df 00 00 12 f6 00 00 12 81 00 00 12 6f 00 00 16 94 00 00 14 e1 00 00 13 de 00 00 12 f8 00 00 12 82 00 00 12 70 00 00 16 aa 00 00 14 e1 00 00 13 de 00 00 12 fa 00 00 12 83 00 00 12 70 00 00 16 a9 00 00 14 e3 00 00 13 e0 00 00 12 fc 00 00 12 85 00 00 12 72 00 00 16 8a 00 00 14 eb 00 00 13 e4 00 00 12 fc 00 00 12 85 00 00 12 73 00 00 16 90 00 00 14 f3 00 00 13 e4 00 00 13 01 00 00 12 86 00 00 12 74 00 00 16 8a 00 00 14 eb 00 00 13 fa 00 00 13 03 00 00 12 88 00 00 12 75 00 00 16 94 00 00 15 00 00 00 13 f6 00 00 12 ff 00 00 12 8a 00 00 12 76 00 00 16 a2 00 00 14 fa 00 00 13 fb 00 00 13 05 00 00 12 89 00 00 12 75 00 00 16 a5 00 00 15 00 00 00 13 f1 00 00 13 06 00 00 12 89 00 00 12 76 00 00 16 d0 00 00 14 f0 00 00 13 f2 00 00 13 05 00 00 12 8a 00 00 12 77 00 00 16 cf 00 00 14 ef 00 00 13 f4 00 00 13 0d 00 00 12 8b 00 00 12 77 00 00 17 21 00 00 15 06 00 00 13 f4 00 00 13 0e 00 00 12 8e 00 00 12 7a 00 00 17 5e 00 00 15 34 00 00 14 11 00 00 13 17 00 00 12 91 00 00 12 7c 00 00 17 bd 00 00 15 77 00 00 14 48 00 00 13 23 00 00 12 95 00 00 12 80 00 00 17 bd 00 00 15 77 00 00 14 48 00 00 13 23 00 00 12 95 00 00 12 80 00 00 17 bd 00 00 15 77 00 00 14 48 00 00 13 23 00 00 12 95 00 00 12 80];
	};

	qcom,pc-temp-y2-lut {
		qcom,lut-col-legend = <0xfffffff6 0 10 25 40 50>;
		qcom,lut-row-legend = <10000 9800 9600 9400 9200 9000 8800 8600
		                       8400 8200 8000 7800 7600 7400 7200 7000
		                       6800 6600 6400 6200 6000 5800 5600 5400
		                       5200 5000 4800 4600 4400 4200 4000 3800
		                       3600 3400 3200 3000 2800 2600 2400 2200
		                       2000 1800 1600 1400 1200 1000 900 800
		                       700 600 500 400 300 200 100 0>;
		qcom,lut-data = [00 00 28 c5 00 00 2a d4 00 00 2c 9a 00 00 2d 7e 00 00 2e c2 00 00 30 7c 00 00 29 09 00 00 2b 15 00 00 2c 8c 00 00 2d 7f 00 00 2e e1 00 00 30 6b 00 00 29 57 00 00 2b 3e 00 00 2c 7a 00 00 2d 75 00 00 2e e9 00 00 30 45 00 00 29 a4 00 00 2b 54 00 00 2c 65 00 00 2d 63 00 00 2e e0 00 00 30 17 00 00 29 e3 00 00 2b 5d 00 00 2c 4e 00 00 2d 4c 00 00 2e cb 00 00 2f f2 00 00 2a 0a 00 00 2b 5f 00 00 2c 37 00 00 2d 35 00 00 2e af 00 00 2f e3 00 00 2a 1d 00 00 2b 4f 00 00 2c 1d 00 00 2d 18 00 00 2e 79 00 00 2f c0 00 00 2a 2a 00 00 2b 34 00 00 2c 01 00 00 2c f7 00 00 2e 47 00 00 2f 90 00 00 2a 33 00 00 2b 20 00 00 2b e5 00 00 2c cc 00 00 2e 35 00 00 2f 5c 00 00 2a 39 00 00 2b 0e 00 00 2b c7 00 00 2c 99 00 00 2e 28 00 00 2f 07 00 00 2a 40 00 00 2b 06 00 00 2b b2 00 00 2c 8d 00 00 2e 24 00 00 2e ec 00 00 2a 48 00 00 2b 09 00 00 2b a2 00 00 2c ac 00 00 2e 18 00 00 2f 1b 00 00 2a 54 00 00 2b 0f 00 00 2b 99 00 00 2c c6 00 00 2e 0f 00 00 2f 45 00 00 2a 6f 00 00 2b 1c 00 00 2b a1 00 00 2c b9 00 00 2e 12 00 00 2f 34 00 00 2a a7 00 00 2b 3e 00 00 2b bb 00 00 2c a1 00 00 2e 1a 00 00 2f 0e 00 00 2a d9 00 00 2b 65 00 00 2b da 00 00 2c a0 00 00 2e 24 00 00 2f 06 00 00 2b 02 00 00 2b 8f 00 00 2c 05 00 00 2c bd 00 00 2e 32 00 00 2f 1a 00 00 2b 20 00 00 2b bd 00 00 2c 37 00 00 2c e8 00 00 2e 38 00 00 2f 29 00 00 2b 27 00 00 2b ee 00 00 2c 77 00 00 2d 34 00 00 2e 1a 00 00 2f 3b 00 00 2b 25 00 00 2c 23 00 00 2c b3 00 00 2d 94 00 00 2d f2 00 00 2f 5d 00 00 2b 1e 00 00 2c 34 00 00 2c b9 00 00 2d e6 00 00 2e 3b 00 00 2f 8b 00 00 2b 12 00 00 2c 08 00 00 2c a5 00 00 2e 34 00 00 2f 7e 00 00 2f e8 00 00 2a f9 00 00 2b d8 00 00 2c 9a 00 00 2e 49 00 00 30 1b 00 00 30 4a 00 00 2a 0a 00 00 2b e4 00 00 2c a6 00 00 2d f0 00 00 2f 98 00 00 30 b2 00 00 27 a5 00 00 2c 0e 00 00 2c bc 00 00 2d 96 00 00 2f 03 00 00 31 08 00 00 26 81 00 00 2c 20 00 00 2c d1 00 00 2d 94 00 00 2f 06 00 00 31 18 00 00 26 49 00 00 2c 22 00 00 2c e9 00 00 2d 9b 00 00 2f 31 00 00 31 03 00 00 26 28 00 00 2c 23 00 00 2c f9 00 00 2d a7 00 00 2f 57 00 00 31 0e 00 00 26 0e 00 00 2c 24 00 00 2d 02 00 00 2d c9 00 00 2f 7d 00 00 31 48 00 00 25 fa 00 00 2c 28 00 00 2d 09 00 00 2d ee 00 00 2f a3 00 00 31 7b 00 00 25 f0 00 00 2c 2b 00 00 2d 12 00 00 2e 08 00 00 2f d0 00 00 31 77 00 00 25 ea 00 00 2c 2a 00 00 2d 21 00 00 2e 1d 00 00 30 00 00 00 31 5f 00 00 25 e5 00 00 2c 23 00 00 2d 24 00 00 2e 22 00 00 30 0b 00 00 31 7d 00 00 25 e0 00 00 2c 10 00 00 2d 19 00 00 2e 1d 00 00 2f ed 00 00 31 b8 00 00 25 db 00 00 2b ea 00 00 2d 0d 00 00 2e 1a 00 00 2f d7 00 00 31 d7 00 00 25 d6 00 00 2b c3 00 00 2c fc 00 00 2e 2f 00 00 2f ea 00 00 31 a9 00 00 25 d2 00 00 2b 9c 00 00 2c e2 00 00 2e 4e 00 00 30 06 00 00 31 5c 00 00 25 ce 00 00 2b 6c 00 00 2c d1 00 00 2e 44 00 00 2f fd 00 00 31 54 00 00 25 cb 00 00 2b 30 00 00 2c c4 00 00 2e 1d 00 00 2f e3 00 00 31 86 00 00 25 c8 00 00 2a d8 00 00 2c b0 00 00 2e 11 00 00 2f d4 00 00 31 a2 00 00 25 c6 00 00 29 fa 00 00 2c 68 00 00 2e 22 00 00 2f cf 00 00 31 64 00 00 25 c5 00 00 27 52 00 00 2c 08 00 00 2e 23 00 00 2f c0 00 00 31 0d 00 00 25 c3 00 00 26 39 00 00 2b b2 00 00 2d e7 00 00 2f 71 00 00 30 a0 00 00 25 c2 00 00 25 ff 00 00 2b 1b 00 00 2d fd 00 00 2f a9 00 00 31 05 00 00 25 c0 00 00 25 e0 00 00 2a af 00 00 2d 91 00 00 2f 60 00 00 30 96 00 00 25 bf 00 00 25 d4 00 00 2a 19 00 00 2d 94 00 00 2f 36 00 00 30 15 00 00 25 c2 00 00 25 cd 00 00 29 1d 00 00 2d 8e 00 00 2f 09 00 00 2f 86 00 00 25 cf 00 00 25 c8 00 00 28 31 00 00 2d a1 00 00 2e c3 00 00 2f 2c 00 00 25 f2 00 00 25 c3 00 00 27 ae 00 00 2d 81 00 00 2e b0 00 00 2f 61 00 00 26 1f 00 00 25 bf 00 00 26 58 00 00 2d 4f 00 00 2e 92 00 00 2f 64 00 00 25 b8 00 00 25 bd 00 00 25 e2 00 00 2c dd 00 00 2e 4f 00 00 2e fe 00 00 25 b2 00 00 25 e7 00 00 25 c2 00 00 2c 58 00 00 2d fd 00 00 2e 92 00 00 25 b0 00 00 25 b9 00 00 26 5b 00 00 2b f3 00 00 2d 73 00 00 2e 2c 00 00 25 b2 00 00 25 b2 00 00 25 f9 00 00 2c 04 00 00 2c fc 00 00 2d 32 00 00 25 b2 00 00 25 b2 00 00 25 f9 00 00 2c 04 00 00 2c fc 00 00 2d 32 00 00 25 b2 00 00 25 b2 00 00 25 f9 00 00 2c 04 00 00 2c fc 00 00 2d 32];
	};

	qcom,pc-temp-y3-lut {
		qcom,lut-col-legend = <0xfffffff6 0 10 25 40 50>;
		qcom,lut-row-legend = <10000 9800 9600 9400 9200 9000 8800 8600
		                       8400 8200 8000 7800 7600 7400 7200 7000
		                       6800 6600 6400 6200 6000 5800 5600 5400
		                       5200 5000 4800 4600 4400 4200 4000 3800
		                       3600 3400 3200 3000 2800 2600 2400 2200
		                       2000 1800 1600 1400 1200 1000 900 800
		                       700 600 500 400 300 200 100 0>;
		qcom,lut-data = [00 00 34 64 00 00 34 12 00 00 33 f5 00 00 33 e0 00 00 33 d7 00 00 33 d3 00 00 34 64 00 00 34 14 00 00 33 f6 00 00 33 e0 00 00 33 d6 00 00 33 d3 00 00 34 64 00 00 34 18 00 00 33 f8 00 00 33 e1 00 00 33 d6 00 00 33 d3 00 00 34 65 00 00 34 1b 00 00 33 fa 00 00 33 e1 00 00 33 d6 00 00 33 d3 00 00 34 66 00 00 34 1e 00 00 33 fc 00 00 33 e2 00 00 33 d6 00 00 33 d3 00 00 34 67 00 00 34 20 00 00 33 fd 00 00 33 e2 00 00 33 d6 00 00 33 d3 00 00 34 68 00 00 34 20 00 00 33 fd 00 00 33 e3 00 00 33 d6 00 00 33 d4 00 00 34 69 00 00 34 20 00 00 33 fe 00 00 33 e3 00 00 33 d7 00 00 33 d5 00 00 34 69 00 00 34 21 00 00 33 fe 00 00 33 e3 00 00 33 d7 00 00 33 d5 00 00 34 68 00 00 34 22 00 00 33 fe 00 00 33 e3 00 00 33 d7 00 00 33 d5 00 00 34 67 00 00 34 23 00 00 33 fe 00 00 33 e4 00 00 33 d8 00 00 33 d5 00 00 34 64 00 00 34 23 00 00 33 fe 00 00 33 e4 00 00 33 d8 00 00 33 d5 00 00 34 60 00 00 34 23 00 00 33 fe 00 00 33 e5 00 00 33 d8 00 00 33 d6 00 00 34 5f 00 00 34 22 00 00 33 ff 00 00 33 e4 00 00 33 d9 00 00 33 d6 00 00 34 5e 00 00 34 20 00 00 34 00 00 00 33 e4 00 00 33 d9 00 00 33 d6 00 00 34 5d 00 00 34 1f 00 00 34 00 00 00 33 e4 00 00 33 d9 00 00 33 d6 00 00 34 59 00 00 34 1d 00 00 33 ff 00 00 33 e6 00 00 33 db 00 00 33 d6 00 00 34 54 00 00 34 1c 00 00 33 fe 00 00 33 e8 00 00 33 dc 00 00 33 d6 00 00 34 4e 00 00 34 1b 00 00 33 fd 00 00 33 e9 00 00 33 dc 00 00 33 d7 00 00 34 46 00 00 34 1b 00 00 33 fc 00 00 33 ea 00 00 33 db 00 00 33 d8 00 00 34 40 00 00 34 1a 00 00 33 fb 00 00 33 ea 00 00 33 db 00 00 33 d9 00 00 34 3a 00 00 34 14 00 00 33 f9 00 00 33 e9 00 00 33 dd 00 00 33 da 00 00 34 34 00 00 34 0d 00 00 33 f7 00 00 33 e7 00 00 33 de 00 00 33 da 00 00 34 2c 00 00 34 0a 00 00 33 f4 00 00 33 e3 00 00 33 da 00 00 33 d7 00 00 34 21 00 00 34 08 00 00 33 f2 00 00 33 e0 00 00 33 d6 00 00 33 d3 00 00 34 1d 00 00 34 07 00 00 33 f1 00 00 33 e0 00 00 33 d6 00 00 33 d3 00 00 34 1f 00 00 34 05 00 00 33 f0 00 00 33 e0 00 00 33 d6 00 00 33 d3 00 00 34 22 00 00 34 04 00 00 33 f0 00 00 33 e0 00 00 33 d5 00 00 33 d3 00 00 34 22 00 00 34 03 00 00 33 ef 00 00 33 df 00 00 33 d5 00 00 33 d3 00 00 34 20 00 00 34 02 00 00 33 ef 00 00 33 df 00 00 33 d5 00 00 33 d3 00 00 34 21 00 00 34 00 00 00 33 ef 00 00 33 df 00 00 33 d6 00 00 33 d3 00 00 34 2c 00 00 33 fc 00 00 33 ee 00 00 33 e0 00 00 33 d6 00 00 33 d2 00 00 34 3a 00 00 33 f9 00 00 33 ee 00 00 33 e0 00 00 33 d6 00 00 33 d2 00 00 34 48 00 00 33 fa 00 00 33 ee 00 00 33 e0 00 00 33 d6 00 00 33 d3 00 00 34 58 00 00 33 fd 00 00 33 ed 00 00 33 e0 00 00 33 d6 00 00 33 d3 00 00 34 6a 00 00 34 00 00 00 33 ed 00 00 33 e0 00 00 33 d6 00 00 33 d3 00 00 34 81 00 00 34 02 00 00 33 ed 00 00 33 df 00 00 33 d6 00 00 33 d2 00 00 34 9e 00 00 34 05 00 00 33 ee 00 00 33 df 00 00 33 d6 00 00 33 d2 00 00 34 c2 00 00 34 07 00 00 33 ee 00 00 33 de 00 00 33 d5 00 00 33 d2 00 00 34 f0 00 00 34 0a 00 00 33 ef 00 00 33 de 00 00 33 d5 00 00 33 d2 00 00 35 24 00 00 34 0e 00 00 33 f0 00 00 33 de 00 00 33 d5 00 00 33 d3 00 00 35 62 00 00 34 14 00 00 33 f2 00 00 33 de 00 00 33 d6 00 00 33 d4 00 00 35 af 00 00 34 1d 00 00 33 f4 00 00 33 de 00 00 33 d6 00 00 33 d4 00 00 36 16 00 00 34 2c 00 00 33 f5 00 00 33 de 00 00 33 d5 00 00 33 d4 00 00 36 ac 00 00 34 45 00 00 33 f5 00 00 33 dc 00 00 33 d5 00 00 33 d3 00 00 37 70 00 00 34 69 00 00 33 fd 00 00 33 df 00 00 33 d6 00 00 33 d4 00 00 38 3f 00 00 34 91 00 00 34 00 00 00 33 e1 00 00 33 d7 00 00 33 d6 00 00 39 3b 00 00 34 d8 00 00 34 06 00 00 33 e4 00 00 33 db 00 00 33 d7 00 00 3a 1a 00 00 35 47 00 00 34 19 00 00 33 e7 00 00 33 dc 00 00 33 d8 00 00 3b db 00 00 36 09 00 00 34 37 00 00 33 e6 00 00 33 db 00 00 33 d7 00 00 39 70 00 00 37 b3 00 00 34 7e 00 00 33 e6 00 00 33 d9 00 00 33 d6 00 00 3c f7 00 00 39 ef 00 00 35 ef 00 00 33 e8 00 00 33 db 00 00 33 d7 00 00 49 07 00 00 37 37 00 00 39 9f 00 00 33 ed 00 00 33 db 00 00 33 d8 00 00 81 42 00 00 3b 50 00 00 36 b6 00 00 34 04 00 00 33 de 00 00 33 da 00 00 81 42 00 00 3b 50 00 00 36 b6 00 00 34 04 00 00 33 de 00 00 33 da 00 00 81 42 00 00 3b 50 00 00 36 b6 00 00 34 04 00 00 33 de 00 00 33 da];
	};

	qcom,pc-temp-y4-lut {
		qcom,lut-col-legend = <0xfffffff6 0 10 25 40 50>;
		qcom,lut-row-legend = <10000 9800 9600 9400 9200 9000 8800 8600
		                       8400 8200 8000 7800 7600 7400 7200 7000
		                       6800 6600 6400 6200 6000 5800 5600 5400
		                       5200 5000 4800 4600 4400 4200 4000 3800
		                       3600 3400 3200 3000 2800 2600 2400 2200
		                       2000 1800 1600 1400 1200 1000 900 800
		                       700 600 500 400 300 200 100 0>;
		qcom,lut-data = [00 00 40 ea 00 00 40 9a 00 00 40 71 00 00 40 56 00 00 40 3c 00 00 40 35 00 00 41 0c 00 00 40 ac 00 00 40 7f 00 00 40 54 00 00 40 3a 00 00 40 33 00 00 41 48 00 00 40 ca 00 00 40 8d 00 00 40 50 00 00 40 36 00 00 40 30 00 00 41 8a 00 00 40 eb 00 00 40 98 00 00 40 4c 00 00 40 32 00 00 40 2c 00 00 41 c1 00 00 41 06 00 00 40 a0 00 00 40 49 00 00 40 2f 00 00 40 2a 00 00 41 da 00 00 41 10 00 00 40 a2 00 00 40 48 00 00 40 2e 00 00 40 28 00 00 41 de 00 00 41 0f 00 00 40 9f 00 00 40 47 00 00 40 2e 00 00 40 27 00 00 41 e0 00 00 41 0d 00 00 40 9a 00 00 40 47 00 00 40 2e 00 00 40 27 00 00 41 de 00 00 41 08 00 00 40 95 00 00 40 47 00 00 40 2e 00 00 40 27 00 00 41 d7 00 00 41 00 00 00 40 90 00 00 40 48 00 00 40 2f 00 00 40 28 00 00 41 d4 00 00 40 fc 00 00 40 8e 00 00 40 4a 00 00 40 30 00 00 40 28 00 00 41 d9 00 00 40 fc 00 00 40 8e 00 00 40 4b 00 00 40 31 00 00 40 29 00 00 41 e3 00 00 40 fc 00 00 40 8f 00 00 40 4e 00 00 40 33 00 00 40 2b 00 00 41 f2 00 00 41 00 00 00 40 92 00 00 40 53 00 00 40 36 00 00 40 2c 00 00 42 08 00 00 41 10 00 00 40 9a 00 00 40 5a 00 00 40 3a 00 00 40 2f 00 00 42 12 00 00 41 24 00 00 40 a5 00 00 40 61 00 00 40 3d 00 00 40 32 00 00 42 0f 00 00 41 48 00 00 40 b7 00 00 40 68 00 00 40 40 00 00 40 36 00 00 42 07 00 00 41 69 00 00 40 ce 00 00 40 71 00 00 40 44 00 00 40 3b 00 00 41 ef 00 00 41 6f 00 00 40 f0 00 00 40 81 00 00 40 4d 00 00 40 3f 00 00 41 b4 00 00 41 72 00 00 41 13 00 00 40 95 00 00 40 59 00 00 40 44 00 00 41 7d 00 00 41 70 00 00 41 12 00 00 40 a3 00 00 40 67 00 00 40 4e 00 00 41 4f 00 00 41 33 00 00 40 ec 00 00 40 b0 00 00 40 7a 00 00 40 5f 00 00 41 29 00 00 40 e4 00 00 40 c1 00 00 40 b2 00 00 40 81 00 00 40 67 00 00 41 14 00 00 40 c0 00 00 40 94 00 00 40 80 00 00 40 5f 00 00 40 4f 00 00 41 06 00 00 40 a8 00 00 40 6f 00 00 40 4b 00 00 40 38 00 00 40 30 00 00 40 f8 00 00 40 98 00 00 40 64 00 00 40 42 00 00 40 32 00 00 40 2c 00 00 40 e3 00 00 40 8f 00 00 40 5e 00 00 40 3f 00 00 40 30 00 00 40 2b 00 00 40 d5 00 00 40 88 00 00 40 5c 00 00 40 3e 00 00 40 30 00 00 40 2a 00 00 40 d8 00 00 40 80 00 00 40 5d 00 00 40 41 00 00 40 32 00 00 40 2c 00 00 40 e1 00 00 40 79 00 00 40 5d 00 00 40 44 00 00 40 35 00 00 40 2e 00 00 40 e6 00 00 40 73 00 00 40 5e 00 00 40 4a 00 00 40 39 00 00 40 32 00 00 40 e6 00 00 40 6e 00 00 40 60 00 00 40 51 00 00 40 3e 00 00 40 37 00 00 40 e7 00 00 40 6a 00 00 40 60 00 00 40 57 00 00 40 44 00 00 40 3c 00 00 40 ea 00 00 40 6c 00 00 40 5f 00 00 40 5d 00 00 40 4d 00 00 40 43 00 00 40 f0 00 00 40 72 00 00 40 5d 00 00 40 5f 00 00 40 51 00 00 40 47 00 00 40 f6 00 00 40 7a 00 00 40 5f 00 00 40 5f 00 00 40 4c 00 00 40 41 00 00 40 fe 00 00 40 88 00 00 40 62 00 00 40 5d 00 00 40 41 00 00 40 35 00 00 41 05 00 00 40 98 00 00 40 65 00 00 40 55 00 00 40 39 00 00 40 2f 00 00 41 0b 00 00 40 a6 00 00 40 68 00 00 40 42 00 00 40 32 00 00 40 2c 00 00 41 10 00 00 40 b2 00 00 40 6c 00 00 40 3b 00 00 40 2f 00 00 40 2b 00 00 41 11 00 00 40 ba 00 00 40 70 00 00 40 3e 00 00 40 30 00 00 40 2b 00 00 41 0c 00 00 40 c0 00 00 40 74 00 00 40 3f 00 00 40 30 00 00 40 2b 00 00 41 07 00 00 40 c1 00 00 40 7b 00 00 40 3f 00 00 40 2e 00 00 40 29 00 00 41 03 00 00 40 c1 00 00 40 7b 00 00 40 3e 00 00 40 2d 00 00 40 27 00 00 41 08 00 00 40 be 00 00 40 6c 00 00 40 34 00 00 40 25 00 00 40 20 00 00 41 09 00 00 40 b9 00 00 40 7d 00 00 40 43 00 00 40 2e 00 00 40 27 00 00 41 13 00 00 40 c2 00 00 40 92 00 00 40 4c 00 00 40 32 00 00 40 2b 00 00 41 1a 00 00 40 ce 00 00 40 b0 00 00 40 5c 00 00 40 3b 00 00 40 3a 00 00 41 03 00 00 40 e2 00 00 40 d9 00 00 40 73 00 00 40 62 00 00 40 64 00 00 40 e8 00 00 40 ff 00 00 40 ff 00 00 40 6d 00 00 40 48 00 00 40 47 00 00 59 4f 00 00 41 27 00 00 41 1b 00 00 40 63 00 00 40 35 00 00 40 33 00 00 79 1e 00 00 41 35 00 00 41 69 00 00 40 76 00 00 40 3e 00 00 40 3b 00 00 e8 e9 00 00 57 53 00 00 42 8b 00 00 40 9d 00 00 40 48 00 00 40 46 00 00 71 46 00 00 8f 46 00 00 6c 6e 00 00 41 0d 00 00 40 7e 00 00 40 84 00 00 71 46 00 00 8f 46 00 00 6c 6e 00 00 41 0d 00 00 40 7e 00 00 40 84 00 00 71 46 00 00 8f 46 00 00 6c 6e 00 00 41 0d 00 00 40 7e 00 00 40 84];
	};

	qcom,pc-temp-y5-lut {
		qcom,lut-col-legend = <0xfffffff6 0 10 25 40 50>;
		qcom,lut-row-legend = <10000 9800 9600 9400 9200 9000 8800 8600
		                       8400 8200 8000 7800 7600 7400 7200 7000
		                       6800 6600 6400 6200 6000 5800 5600 5400
		                       5200 5000 4800 4600 4400 4200 4000 3800
		                       3600 3400 3200 3000 2800 2600 2400 2200
		                       2000 1800 1600 1400 1200 1000 900 800
		                       700 600 500 400 300 200 100 0>;
		qcom,lut-data = [00 00 40 86 00 00 4a d4 00 00 51 50 00 00 4d f6 00 00 56 22 00 00 51 e5 00 00 41 b2 00 00 4d 34 00 00 55 29 00 00 53 eb 00 00 59 26 00 00 52 be 00 00 43 16 00 00 4f ce 00 00 57 eb 00 00 57 4e 00 00 5b 05 00 00 57 31 00 00 44 a9 00 00 52 31 00 00 59 bf 00 00 58 d6 00 00 5b e8 00 00 5d 41 00 00 46 65 00 00 53 ed 00 00 5a c6 00 00 59 37 00 00 5b f9 00 00 62 ea 00 00 48 41 00 00 54 91 00 00 5b 25 00 00 59 1c 00 00 5b 60 00 00 66 43 00 00 4a da 00 00 54 37 00 00 5a 87 00 00 57 53 00 00 59 c0 00 00 6a dd 00 00 4d 1c 00 00 53 8f 00 00 59 50 00 00 54 d7 00 00 57 84 00 00 6e b6 00 00 4d 66 00 00 53 0f 00 00 57 b4 00 00 52 b7 00 00 55 34 00 00 6b a2 00 00 4d 58 00 00 52 8a 00 00 54 dc 00 00 4f 7d 00 00 52 9d 00 00 63 5a 00 00 4d 38 00 00 51 ce 00 00 51 f1 00 00 4d 1c 00 00 50 69 00 00 5d cd 00 00 4b 8b 00 00 4f c8 00 00 4e c5 00 00 4b 94 00 00 4e a3 00 00 5b 25 00 00 49 7b 00 00 4c d7 00 00 4b f6 00 00 49 ee 00 00 4c cf 00 00 58 be 00 00 49 dc 00 00 49 b6 00 00 4a 01 00 00 46 32 00 00 4a 0d 00 00 55 ba 00 00 4c a1 00 00 45 f8 00 00 48 0e 00 00 41 85 00 00 47 23 00 00 52 64 00 00 4f e3 00 00 44 7c 00 00 45 ce 00 00 40 b9 00 00 46 cc 00 00 4e 75 00 00 54 15 00 00 45 68 00 00 42 3a 00 00 41 94 00 00 48 b1 00 00 49 0a 00 00 57 db 00 00 47 6a 00 00 40 1c 00 00 42 56 00 00 49 f3 00 00 46 09 00 00 59 54 00 00 4d 19 00 00 41 ac 00 00 42 bc 00 00 46 4c 00 00 46 ad 00 00 5a 60 00 00 59 09 00 00 45 99 00 00 43 54 00 00 40 e7 00 00 48 2a 00 00 5a ca 00 00 5d f7 00 00 4b f4 00 00 46 68 00 00 41 8e 00 00 49 e0 00 00 5b 37 00 00 5d 51 00 00 58 08 00 00 4f 8e 00 00 48 70 00 00 4c 52 00 00 5b 62 00 00 5c 9e 00 00 5f 9c 00 00 57 08 00 00 4f 7c 00 00 4f af 00 00 55 50 00 00 5d 6a 00 00 61 91 00 00 5b eb 00 00 56 43 00 00 56 2a 00 00 44 b4 00 00 5f ee 00 00 62 64 00 00 5f cc 00 00 5b 86 00 00 5d 13 00 00 3b 65 00 00 61 6e 00 00 62 6c 00 00 63 2d 00 00 5d 12 00 00 60 a0 00 00 38 4d 00 00 62 15 00 00 62 83 00 00 66 5e 00 00 5e 08 00 00 63 31 00 00 36 5a 00 00 62 77 00 00 62 e6 00 00 66 5c 00 00 5e 03 00 00 63 bc 00 00 34 de 00 00 62 75 00 00 63 81 00 00 5f c0 00 00 5a 93 00 00 5f d7 00 00 33 92 00 00 62 14 00 00 64 10 00 00 5a df 00 00 57 03 00 00 5a 04 00 00 33 2f 00 00 60 76 00 00 64 13 00 00 5d 35 00 00 55 d9 00 00 53 c5 00 00 34 50 00 00 54 1d 00 00 63 9b 00 00 61 44 00 00 55 1c 00 00 4d 2a 00 00 35 8a 00 00 49 26 00 00 64 05 00 00 61 f1 00 00 54 a0 00 00 4b c4 00 00 36 50 00 00 4a db 00 00 66 13 00 00 61 3b 00 00 53 21 00 00 4e 0f 00 00 37 9c 00 00 50 28 00 00 67 8a 00 00 60 d0 00 00 52 32 00 00 51 1d 00 00 38 4d 00 00 53 fe 00 00 65 c3 00 00 63 53 00 00 59 36 00 00 54 0a 00 00 38 94 00 00 58 23 00 00 62 71 00 00 67 5c 00 00 63 8d 00 00 57 51 00 00 38 d5 00 00 5b 7f 00 00 61 84 00 00 6a 14 00 00 64 6f 00 00 5a 95 00 00 39 43 00 00 5c fb 00 00 62 94 00 00 6c 65 00 00 61 96 00 00 5d c0 00 00 39 c7 00 00 5d b6 00 00 63 0c 00 00 6c 55 00 00 5f b8 00 00 61 e0 00 00 3a 1a 00 00 5b 00 00 00 60 ec 00 00 65 99 00 00 5f 87 00 00 69 df 00 00 3a 38 00 00 4b 32 00 00 5d cd 00 00 61 d2 00 00 5f 9d 00 00 72 35 00 00 39 6e 00 00 40 98 00 00 59 d1 00 00 60 45 00 00 5f bd 00 00 78 4c 00 00 36 d2 00 00 3b 57 00 00 56 e9 00 00 60 b7 00 00 61 1c 00 00 77 ed 00 00 36 56 00 00 3a 04 00 00 57 4b 00 00 58 be 00 00 68 21 00 00 77 6a 00 00 35 0d 00 00 39 15 00 00 54 10 00 00 56 c6 00 00 57 5e 00 00 60 d4 00 00 35 49 00 00 37 f2 00 00 4c e8 00 00 53 93 00 00 51 9f 00 00 63 e1 00 00 36 c2 00 00 37 d3 00 00 45 e2 00 00 57 c0 00 00 69 82 00 00 6a de 00 00 52 66 00 00 37 0f 00 00 49 4b 00 00 5b e6 00 00 64 c4 00 00 60 c4 00 00 73 8b 00 00 37 fa 00 00 46 02 00 00 63 1d 00 00 6a fa 00 00 68 c9 00 00 25 bc 00 00 38 fd 00 00 40 4e 00 00 63 e5 00 00 6c 11 00 00 73 68 00 00 22 fd 00 00 49 94 00 00 38 11 00 00 62 45 00 00 77 68 00 00 77 e1 00 00 23 5d 00 00 24 8e 00 00 38 99 00 00 5f f6 00 00 6c 0c 00 00 6e 4c 00 00 23 12 00 00 23 9e 00 00 2a 58 00 00 5f 03 00 00 67 d3 00 00 6a b3 00 00 23 12 00 00 23 9e 00 00 2a 58 00 00 5f 03 00 00 67 d3 00 00 6a b3 00 00 23 12 00 00 23 9e 00 00 2a 58 00 00 5f 03 00 00 67 d3 00 00 6a b3];
	};

	qcom,pc-temp-y6-lut {
		qcom,lut-col-legend = <0xfffffff6 0 10 25 40 50>;
		qcom,lut-row-legend = <10000 9800 9600 9400 9200 9000 8800 8600
		                       8400 8200 8000 7800 7600 7400 7200 7000
		                       6800 6600 6400 6200 6000 5800 5600 5400
		                       5200 5000 4800 4600 4400 4200 4000 3800
		                       3600 3400 3200 3000 2800 2600 2400 2200
		                       2000 1800 1600 1400 1200 1000 900 800
		                       700 600 500 400 300 200 100 0>;
		qcom,lut-data = [00 00 15 a4 00 00 14 5b 00 00 13 dd 00 00 13 7a 00 00 13 58 00 00 13 51 00 00 15 ab 00 00 14 66 00 00 13 de 00 00 13 79 00 00 13 57 00 00 13 50 00 00 15 b0 00 00 14 6d 00 00 13 df 00 00 13 77 00 00 13 56 00 00 13 4f 00 00 15 b2 00 00 14 71 00 00 13 df 00 00 13 76 00 00 13 55 00 00 13 4e 00 00 15 b3 00 00 14 72 00 00 13 de 00 00 13 75 00 00 13 54 00 00 13 4e 00 00 15 b3 00 00 14 72 00 00 13 dd 00 00 13 75 00 00 13 54 00 00 13 4e 00 00 15 b0 00 00 14 6f 00 00 13 db 00 00 13 74 00 00 13 54 00 00 13 4e 00 00 15 a9 00 00 14 69 00 00 13 d7 00 00 13 74 00 00 13 55 00 00 13 4f 00 00 15 a3 00 00 14 64 00 00 13 d4 00 00 13 74 00 00 13 55 00 00 13 4f 00 00 15 9c 00 00 14 60 00 00 13 d0 00 00 13 74 00 00 13 55 00 00 13 50 00 00 15 98 00 00 14 5d 00 00 13 ce 00 00 13 75 00 00 13 56 00 00 13 50 00 00 15 96 00 00 14 59 00 00 13 cc 00 00 13 75 00 00 13 57 00 00 13 51 00 00 15 95 00 00 14 56 00 00 13 cb 00 00 13 77 00 00 13 58 00 00 13 52 00 00 15 96 00 00 14 56 00 00 13 cc 00 00 13 78 00 00 13 59 00 00 13 53 00 00 15 99 00 00 14 58 00 00 13 cd 00 00 13 79 00 00 13 5b 00 00 13 54 00 00 15 9b 00 00 14 5b 00 00 13 d0 00 00 13 7c 00 00 13 5c 00 00 13 55 00 00 15 99 00 00 14 64 00 00 13 d3 00 00 13 7f 00 00 13 5e 00 00 13 56 00 00 15 96 00 00 14 6d 00 00 13 d8 00 00 13 83 00 00 13 61 00 00 13 58 00 00 15 8e 00 00 14 6e 00 00 13 e1 00 00 13 89 00 00 13 63 00 00 13 5a 00 00 15 7b 00 00 14 6e 00 00 13 eb 00 00 13 8f 00 00 13 66 00 00 13 5d 00 00 15 6b 00 00 14 6d 00 00 13 ea 00 00 13 93 00 00 13 6a 00 00 13 60 00 00 15 5f 00 00 14 59 00 00 13 de 00 00 13 96 00 00 13 71 00 00 13 66 00 00 15 54 00 00 14 3f 00 00 13 d1 00 00 13 96 00 00 13 74 00 00 13 68 00 00 15 4a 00 00 14 35 00 00 13 c2 00 00 13 86 00 00 13 68 00 00 13 5f 00 00 15 40 00 00 14 2e 00 00 13 b7 00 00 13 74 00 00 13 5a 00 00 13 54 00 00 15 3c 00 00 14 2c 00 00 13 b4 00 00 13 72 00 00 13 58 00 00 13 52 00 00 15 3f 00 00 14 2b 00 00 13 b3 00 00 13 71 00 00 13 57 00 00 13 52 00 00 15 43 00 00 14 2b 00 00 13 b3 00 00 13 71 00 00 13 57 00 00 13 52 00 00 15 4a 00 00 14 2b 00 00 13 b4 00 00 13 72 00 00 13 58 00 00 13 53 00 00 15 57 00 00 14 2c 00 00 13 b6 00 00 13 73 00 00 13 59 00 00 13 54 00 00 15 66 00 00 14 2d 00 00 13 b7 00 00 13 75 00 00 13 5a 00 00 13 55 00 00 15 78 00 00 14 2e 00 00 13 b9 00 00 13 78 00 00 13 5c 00 00 13 56 00 00 15 8c 00 00 14 30 00 00 13 bb 00 00 13 7b 00 00 13 5e 00 00 13 57 00 00 15 a1 00 00 14 35 00 00 13 bc 00 00 13 7d 00 00 13 61 00 00 13 5a 00 00 15 b8 00 00 14 42 00 00 13 be 00 00 13 7e 00 00 13 62 00 00 13 5b 00 00 15 d2 00 00 14 4f 00 00 13 c0 00 00 13 7e 00 00 13 61 00 00 13 59 00 00 15 f1 00 00 14 5d 00 00 13 c3 00 00 13 7e 00 00 13 5e 00 00 13 56 00 00 16 13 00 00 14 6e 00 00 13 c7 00 00 13 7c 00 00 13 5c 00 00 13 54 00 00 16 3b 00 00 14 80 00 00 13 cb 00 00 13 77 00 00 13 59 00 00 13 53 00 00 16 67 00 00 14 93 00 00 13 cf 00 00 13 75 00 00 13 58 00 00 13 53 00 00 16 97 00 00 14 a7 00 00 13 d5 00 00 13 76 00 00 13 59 00 00 13 54 00 00 16 cb 00 00 14 bb 00 00 13 dd 00 00 13 77 00 00 13 5a 00 00 13 55 00 00 17 0a 00 00 14 d5 00 00 13 e9 00 00 13 78 00 00 13 59 00 00 13 54 00 00 17 5c 00 00 14 f9 00 00 13 f4 00 00 13 78 00 00 13 59 00 00 13 53 00 00 17 d1 00 00 15 2b 00 00 13 f5 00 00 13 75 00 00 13 56 00 00 13 51 00 00 18 67 00 00 15 62 00 00 14 13 00 00 13 7c 00 00 13 5a 00 00 13 54 00 00 18 e4 00 00 15 9d 00 00 14 2b 00 00 13 80 00 00 13 5c 00 00 13 56 00 00 19 75 00 00 15 ea 00 00 14 4f 00 00 13 88 00 00 13 61 00 00 13 5c 00 00 1a 44 00 00 16 56 00 00 14 88 00 00 13 91 00 00 13 6e 00 00 13 69 00 00 1b f5 00 00 16 ff 00 00 14 ce 00 00 13 90 00 00 13 65 00 00 13 60 00 00 21 ad 00 00 18 23 00 00 15 45 00 00 13 8d 00 00 13 5f 00 00 13 5a 00 00 2d cd 00 00 19 70 00 00 16 a5 00 00 13 97 00 00 13 63 00 00 13 5d 00 00 56 94 00 00 1e d0 00 00 19 0a 00 00 13 a9 00 00 13 67 00 00 13 61 00 00 5b 44 00 00 32 67 00 00 25 07 00 00 13 da 00 00 13 79 00 00 13 75 00 00 5b 44 00 00 32 67 00 00 25 07 00 00 13 da 00 00 13 79 00 00 13 75 00 00 5b 44 00 00 32 67 00 00 25 07 00 00 13 da 00 00 13 79 00 00 13 75];
	};
};
